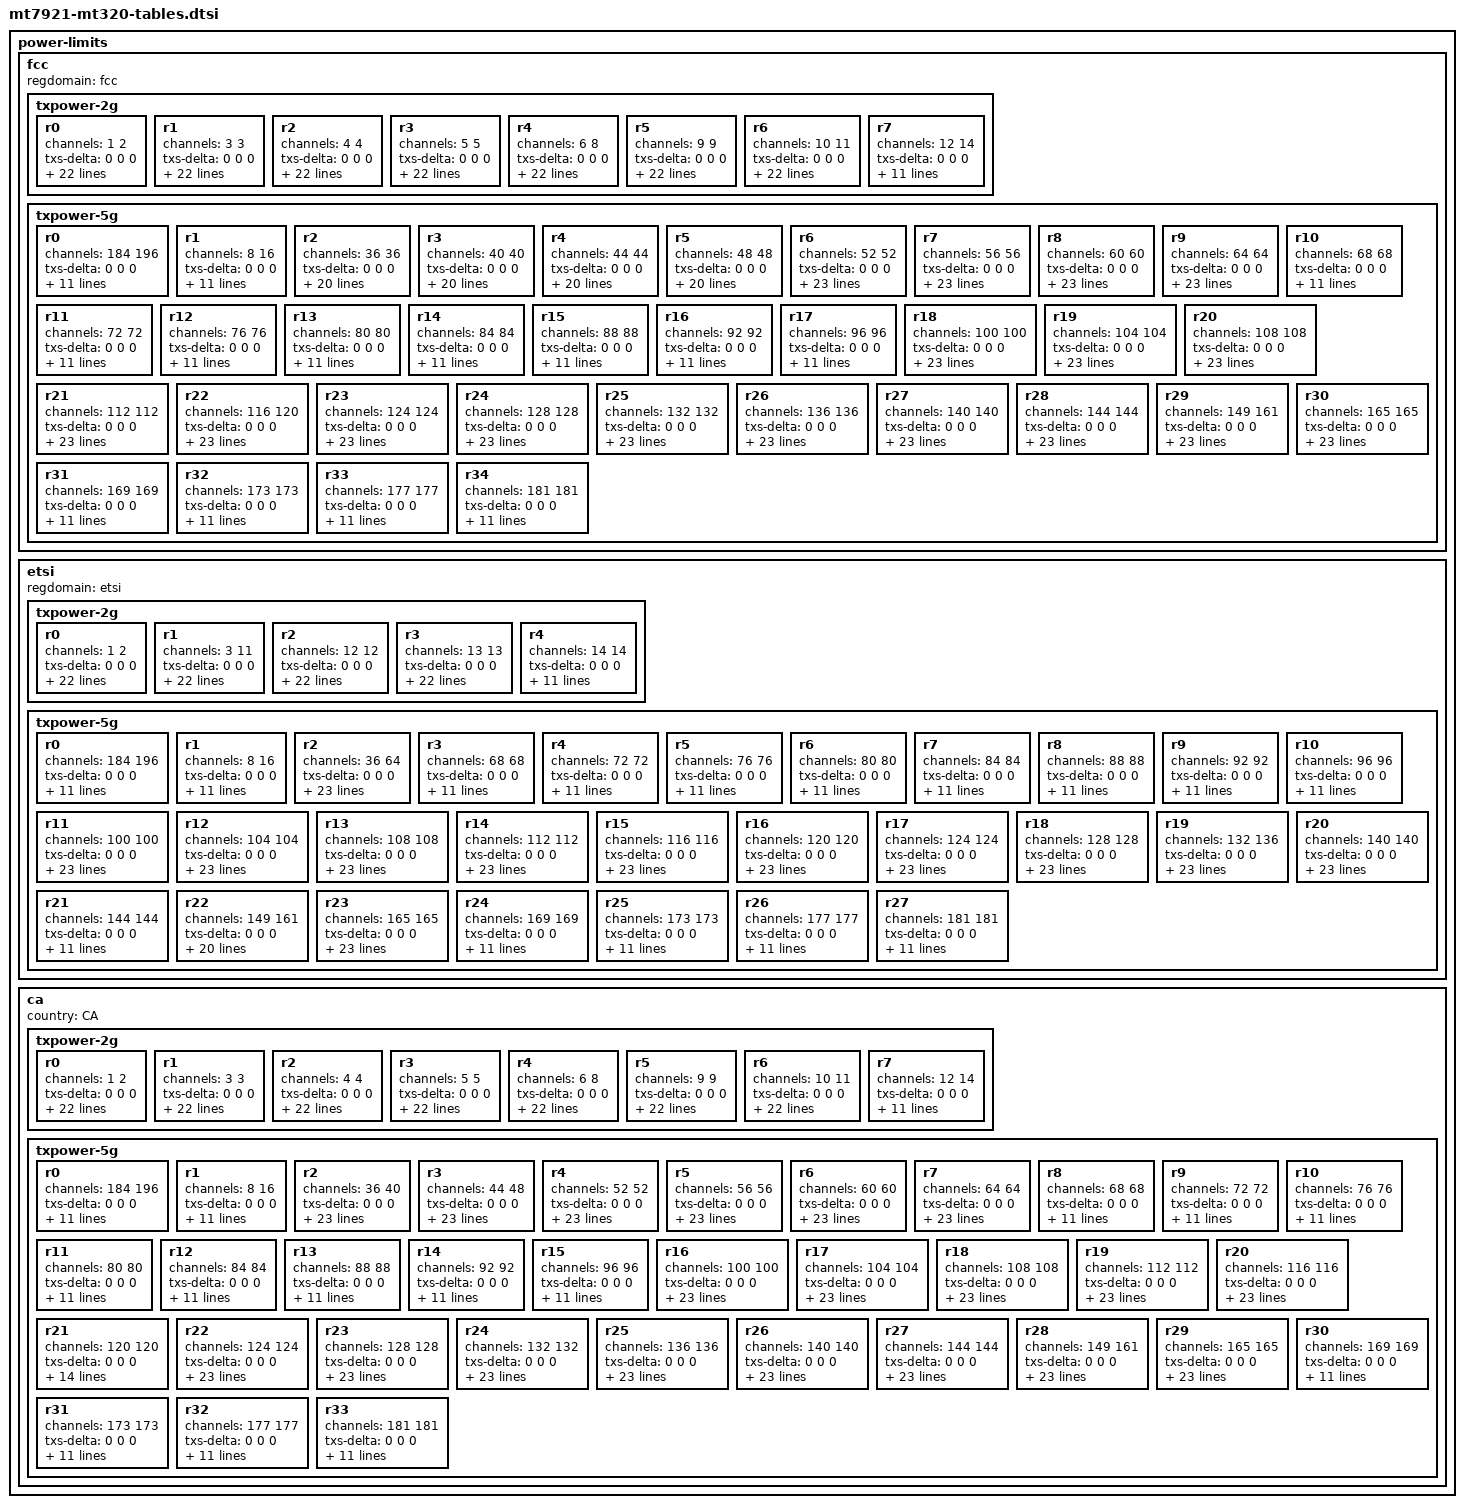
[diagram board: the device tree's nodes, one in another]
power-limits {
	fcc {
		regdomain = "fcc";
		txpower-2g {
			r0 {
				channels = <1 2>;
				txs-delta = <0 0 0>;
				rates-cck = <31 31 31 31>;
				rates-ofdm = <27 27 27 27 27 27 27 27>;
				rates-mcs =
				<1 20 20 20 20 20 20 20 20 20 20>,
				<1 20 0 0 0 0 0 0 0 0 0>,
				<2 126 126 126 126 126 126 126 126 126 126>;
				rates-ru =
				<1 26 26 26 26 26 26 26 26 26 0 0 0>,
				<1 0 0 0 0 0 0 0 0 0 0 0 0>,
				<1 0 18 18 18 18 18 18 18 18 18 18 18>,
				<1 20 20 20 20 20 20 20 20 20 20 20 20>,
				<1 20 0 0 0 0 0 0 0 0 0 0 0>,
				<2 126 126 126 126 126 126 126 126 126 126 126 126>;
				rates-eht-ru =
				<1 26 26 26 26 26 26 26 26 26 0 0 0 0 0 0 0>,
				<1 0 0 0 0 0 0 0 0 0 0 0 0 0 0 0 0>,
				<1 0 18 18 18 18 18 18 18 18 18 18 18 18 20 20 20>,
				<1 20 20 20 20 20 20 20 20 20 20 20 20 20 20 20 20>,
				<1 20 0 0 0 0 0 0 0 0 0 0 0 0 0 0 0>,
				<3 126 126 126 126 126 126 126 126 126 126 126 126 126 126 126 126>,
				<1 0 0 0 0 0 0 0 0 0 0 0 0 0 0 0 0>,
				<1 20 20 20 20 20 20 20 20 20 20 20 20 20 20 20 20>,
				<1 0 0 0 0 0 0 0 0 0 0 0 0 0 0 0 0>,
				<5 126 126 126 126 126 126 126 126 126 126 126 126 126 126 126 126>;
			};
			r1 {
				channels = <3 3>;
				txs-delta = <0 0 0>;
				rates-cck = <32 32 32 32>;
				rates-ofdm = <28 28 28 28 28 28 28 28>;
				rates-mcs =
				<1 20 20 20 20 20 20 20 20 20 20>,
				<1 20 21 21 21 21 21 21 21 21 21>,
				<2 126 126 126 126 126 126 126 126 126 126>;
				rates-ru =
				<1 28 28 28 28 28 28 28 28 28 0 0 0>,
				<1 21 21 21 21 21 21 0 0 0 0 0 0>,
				<1 0 20 20 20 20 20 20 20 20 20 20 20>,
				<1 20 20 20 20 20 20 20 20 20 20 20 20>,
				<1 20 21 21 21 21 21 21 21 21 21 21 21>,
				<2 126 126 126 126 126 126 126 126 126 126 126 126>;
				rates-eht-ru =
				<1 28 28 28 28 28 28 28 28 28 0 0 0 21 21 21 21>,
				<1 21 21 21 21 21 21 0 0 0 0 0 0 0 0 0 0>,
				<1 0 20 20 20 20 20 20 20 20 20 20 20 20 20 20 20>,
				<1 20 20 20 20 20 20 20 20 20 20 20 20 20 20 20 20>,
				<1 20 21 21 21 21 21 21 21 21 21 21 21 21 0 0 0>,
				<3 126 126 126 126 126 126 126 126 126 126 126 126 126 126 126 126>,
				<1 0 0 0 0 0 0 0 0 0 0 0 0 0 0 0 0>,
				<1 20 20 20 20 20 20 20 20 20 20 20 20 20 20 20 20>,
				<1 0 0 0 0 0 0 0 0 0 0 0 0 0 0 0 0>,
				<5 126 126 126 126 126 126 126 126 126 126 126 126 126 126 126 126>;
			};
			r2 {
				channels = <4 4>;
				txs-delta = <0 0 0>;
				rates-cck = <34 34 34 34>;
				rates-ofdm = <30 30 30 30 30 30 30 30>;
				rates-mcs =
				<1 22 22 22 22 22 22 22 22 22 22>,
				<1 22 21 21 21 21 21 21 21 21 21>,
				<2 126 126 126 126 126 126 126 126 126 126>;
				rates-ru =
				<1 30 30 30 30 30 30 30 30 30 0 0 0>,
				<1 21 21 21 21 21 21 0 0 0 0 0 0>,
				<1 0 22 22 22 22 22 22 22 22 22 22 22>,
				<1 22 22 22 22 22 22 22 22 22 22 22 22>,
				<1 22 21 21 21 21 21 21 21 21 21 21 21>,
				<2 126 126 126 126 126 126 126 126 126 126 126 126>;
				rates-eht-ru =
				<1 30 30 30 30 30 30 30 30 30 0 0 0 21 21 21 21>,
				<1 21 21 21 21 21 21 0 0 0 0 0 0 0 0 0 0>,
				<1 0 22 22 22 22 22 22 22 22 22 22 22 22 22 22 22>,
				<1 22 22 22 22 22 22 22 22 22 22 22 22 22 22 22 22>,
				<1 22 21 21 21 21 21 21 21 21 21 21 21 21 0 0 0>,
				<3 126 126 126 126 126 126 126 126 126 126 126 126 126 126 126 126>,
				<1 0 0 0 0 0 0 0 0 0 0 0 0 0 0 0 0>,
				<1 22 22 22 22 22 22 22 22 22 22 22 22 22 22 22 22>,
				<1 0 0 0 0 0 0 0 0 0 0 0 0 0 0 0 0>,
				<5 126 126 126 126 126 126 126 126 126 126 126 126 126 126 126 126>;
			};
			r3 {
				channels = <5 5>;
				txs-delta = <0 0 0>;
				rates-cck = <34 34 34 34>;
				rates-ofdm = <30 30 30 30 30 30 30 30>;
				rates-mcs =
				<1 26 26 26 26 26 24 24 24 24 24>,
				<1 24 21 21 21 21 21 21 21 21 21>,
				<2 126 126 126 126 126 126 126 126 126 126>;
				rates-ru =
				<1 30 30 30 30 30 30 30 30 30 0 0 0>,
				<1 21 21 21 21 21 21 0 0 0 0 0 0>,
				<1 0 26 26 26 26 26 26 26 26 26 26 26>,
				<1 26 26 26 26 26 24 24 24 24 24 24 24>,
				<1 24 21 21 21 21 21 21 21 21 21 21 21>,
				<2 126 126 126 126 126 126 126 126 126 126 126 126>;
				rates-eht-ru =
				<1 30 30 30 30 30 30 30 30 30 0 0 0 21 21 21 21>,
				<1 21 21 21 21 21 21 0 0 0 0 0 0 0 0 0 0>,
				<1 0 26 26 26 26 26 26 26 26 26 26 26 26 26 26 26>,
				<1 26 26 26 26 26 24 24 24 24 24 24 24 24 24 24 24>,
				<1 24 21 21 21 21 21 21 21 21 21 21 21 21 0 0 0>,
				<3 126 126 126 126 126 126 126 126 126 126 126 126 126 126 126 126>,
				<1 0 0 0 0 0 0 0 0 0 0 0 0 0 0 0 0>,
				<1 26 26 26 26 26 26 26 26 26 26 26 26 26 26 26 26>,
				<1 0 0 0 0 0 0 0 0 0 0 0 0 0 0 0 0>,
				<5 126 126 126 126 126 126 126 126 126 126 126 126 126 126 126 126>;
			};
			r4 {
				channels = <6 8>;
				txs-delta = <0 0 0>;
				rates-cck = <34 34 34 34>;
				rates-ofdm = <30 30 30 30 30 30 30 30>;
				rates-mcs =
				<1 26 26 26 26 26 26 26 26 26 26>,
				<1 26 21 21 21 21 21 21 21 21 21>,
				<2 126 126 126 126 126 126 126 126 126 126>;
				rates-ru =
				<1 30 30 30 30 30 30 30 30 30 0 0 0>,
				<1 21 21 21 21 21 21 0 0 0 0 0 0>,
				<1 0 28 28 28 28 28 28 28 28 28 28 28>,
				<1 26 26 26 26 26 26 26 26 26 26 26 26>,
				<1 26 21 21 21 21 21 21 21 21 21 21 21>,
				<2 126 126 126 126 126 126 126 126 126 126 126 126>;
				rates-eht-ru =
				<1 30 30 30 30 30 30 30 30 30 0 0 0 21 21 21 21>,
				<1 21 21 21 21 21 21 0 0 0 0 0 0 0 0 0 0>,
				<1 0 28 28 28 28 28 28 28 28 28 28 28 28 26 26 26>,
				<1 26 26 26 26 26 26 26 26 26 26 26 26 26 26 26 26>,
				<1 26 21 21 21 21 21 21 21 21 21 21 21 21 0 0 0>,
				<3 126 126 126 126 126 126 126 126 126 126 126 126 126 126 126 126>,
				<1 0 0 0 0 0 0 0 0 0 0 0 0 0 0 0 0>,
				<1 26 26 26 26 26 26 26 26 26 26 26 26 26 26 26 26>,
				<1 0 0 0 0 0 0 0 0 0 0 0 0 0 0 0 0>,
				<5 126 126 126 126 126 126 126 126 126 126 126 126 126 126 126 126>;
			};
			r5 {
				channels = <9 9>;
				txs-delta = <0 0 0>;
				rates-cck = <34 34 34 34>;
				rates-ofdm = <28 28 28 28 28 28 28 28>;
				rates-mcs =
				<1 23 23 23 23 23 24 24 24 24 24>,
				<1 24 21 21 21 21 21 21 21 21 21>,
				<2 126 126 126 126 126 126 126 126 126 126>;
				rates-ru =
				<1 27 27 27 27 27 27 27 27 27 0 0 0>,
				<1 21 21 21 21 21 21 0 0 0 0 0 0>,
				<1 0 26 26 26 26 26 26 26 26 26 26 26>,
				<1 23 23 23 23 23 24 24 24 24 24 24 24>,
				<1 24 21 21 21 21 21 21 21 21 21 21 21>,
				<2 126 126 126 126 126 126 126 126 126 126 126 126>;
				rates-eht-ru =
				<1 27 27 27 27 27 27 27 27 27 0 0 0 21 21 21 21>,
				<1 21 21 21 21 21 21 0 0 0 0 0 0 0 0 0 0>,
				<1 0 26 26 26 26 26 26 26 26 26 26 26 26 26 26 26>,
				<1 23 23 23 23 23 24 24 24 24 24 24 24 24 24 24 24>,
				<1 24 21 21 21 21 21 21 21 21 21 21 21 21 0 0 0>,
				<3 126 126 126 126 126 126 126 126 126 126 126 126 126 126 126 126>,
				<1 0 0 0 0 0 0 0 0 0 0 0 0 0 0 0 0>,
				<1 26 26 26 26 26 26 26 26 26 23 23 23 23 23 23 23>,
				<1 0 0 0 0 0 0 0 0 0 0 0 0 0 0 0 0>,
				<5 126 126 126 126 126 126 126 126 126 126 126 126 126 126 126 126>;
			};
			r6 {
				channels = <10 11>;
				txs-delta = <0 0 0>;
				rates-cck = <34 34 34 34>;
				rates-ofdm = <27 27 27 27 27 27 27 27>;
				rates-mcs =
				<1 21 21 21 21 21 24 24 24 24 24>,
				<1 24 0 0 0 0 0 0 0 0 0>,
				<2 126 126 126 126 126 126 126 126 126 126>;
				rates-ru =
				<1 25 25 25 25 25 25 25 25 25 0 0 0>,
				<1 0 0 0 0 0 0 0 0 0 0 0 0>,
				<1 0 22 22 22 22 22 22 22 22 22 22 22>,
				<1 21 21 21 21 21 24 24 24 24 24 24 24>,
				<1 24 0 0 0 0 0 0 0 0 0 0 0>,
				<2 126 126 126 126 126 126 126 126 126 126 126 126>;
				rates-eht-ru =
				<1 25 25 25 25 25 25 25 25 25 0 0 0 0 0 0 0>,
				<1 0 0 0 0 0 0 0 0 0 0 0 0 0 0 0 0>,
				<1 0 22 22 22 22 22 22 22 22 22 22 22 22 25 25 25>,
				<1 21 21 21 21 21 24 24 24 24 24 24 24 24 24 24 24>,
				<1 24 0 0 0 0 0 0 0 0 0 0 0 0 0 0 0>,
				<3 126 126 126 126 126 126 126 126 126 126 126 126 126 126 126 126>,
				<1 0 0 0 0 0 0 0 0 0 0 0 0 0 0 0 0>,
				<1 25 25 25 25 25 25 25 25 25 21 21 21 21 21 21 21>,
				<1 0 0 0 0 0 0 0 0 0 0 0 0 0 0 0 0>,
				<5 126 126 126 126 126 126 126 126 126 126 126 126 126 126 126 126>;
			};
			r7 {
				channels = <12 14>;
				txs-delta = <0 0 0>;
				rates-cck = <0 0 0 0>;
				rates-ofdm = <0 0 0 0 0 0 0 0>;
				rates-mcs =
				<2 0 0 0 0 0 0 0 0 0 0>,
				<2 126 126 126 126 126 126 126 126 126 126>;
				rates-ru =
				<5 0 0 0 0 0 0 0 0 0 0 0 0>,
				<2 126 126 126 126 126 126 126 126 126 126 126 126>;
				rates-eht-ru =
				<5 0 0 0 0 0 0 0 0 0 0 0 0 0 0 0 0>,
				<3 126 126 126 126 126 126 126 126 126 126 126 126 126 126 126 126>,
				<3 0 0 0 0 0 0 0 0 0 0 0 0 0 0 0 0>,
				<5 126 126 126 126 126 126 126 126 126 126 126 126 126 126 126 126>;
			};
		};
		txpower-5g {
			r0 {
				channels = <184 196>;
				txs-delta = <0 0 0>;
				rates-cck = <126 126 126 126>;
				rates-ofdm = <0 0 0 0 0 0 0 0>;
				rates-mcs =
				<2 0 0 0 0 0 0 0 0 0 0>,
				<2 126 126 126 126 126 126 126 126 126 126>;
				rates-ru =
				<5 0 0 0 0 0 0 0 0 0 0 0 0>,
				<2 126 126 126 126 126 126 126 126 126 126 126 126>;
				rates-eht-ru =
				<5 0 0 0 0 0 0 0 0 0 0 0 0 0 0 0 0>,
				<3 126 126 126 126 126 126 126 126 126 126 126 126 126 126 126 126>,
				<3 0 0 0 0 0 0 0 0 0 0 0 0 0 0 0 0>,
				<5 126 126 126 126 126 126 126 126 126 126 126 126 126 126 126 126>;
			};
			r1 {
				channels = <8 16>;
				txs-delta = <0 0 0>;
				rates-cck = <126 126 126 126>;
				rates-ofdm = <0 0 0 0 0 0 0 0>;
				rates-mcs =
				<2 0 0 0 0 0 0 0 0 0 0>,
				<2 126 126 126 126 126 126 126 126 126 126>;
				rates-ru =
				<5 0 0 0 0 0 0 0 0 0 0 0 0>,
				<2 126 126 126 126 126 126 126 126 126 126 126 126>;
				rates-eht-ru =
				<5 0 0 0 0 0 0 0 0 0 0 0 0 0 0 0 0>,
				<3 126 126 126 126 126 126 126 126 126 126 126 126 126 126 126 126>,
				<3 0 0 0 0 0 0 0 0 0 0 0 0 0 0 0 0>,
				<5 126 126 126 126 126 126 126 126 126 126 126 126 126 126 126 126>;
			};
			r2 {
				channels = <36 36>;
				txs-delta = <0 0 0>;
				rates-cck = <126 126 126 126>;
				rates-ofdm = <0 0 0 0 23 23 23 23>;
				rates-mcs =
				<2 22 22 22 22 22 22 22 22 22 22>,
				<2 126 126 126 126 126 126 126 126 126 126>;
				rates-ru =
				<1 23 23 23 23 23 23 23 23 23 23 23 23>,
				<1 22 22 22 22 22 22 22 22 22 22 0 0>,
				<1 0 0 0 0 0 18 18 18 18 18 18 18>,
				<2 22 22 22 22 22 22 22 22 22 22 22 22>,
				<2 126 126 126 126 126 126 126 126 126 126 126 126>;
				rates-eht-ru =
				<1 23 23 23 23 23 23 23 23 23 23 23 23 23 0 0 0>,
				<1 22 22 22 22 22 22 22 22 22 22 0 0 0 16 16 16>,
				<1 0 0 0 0 0 18 18 18 18 18 18 18 18 18 18 18>,
				<2 22 22 22 22 22 22 22 22 22 22 22 22 22 22 22 22>,
				<3 126 126 126 126 126 126 126 126 126 126 126 126 126 126 126 126>,
				<1 16 16 16 16 16 16 16 0 0 0 0 0 0 0 0 0>,
				<1 18 18 18 18 18 18 18 18 18 18 18 18 18 22 22 22>,
				<1 16 16 16 16 16 16 16 16 16 16 16 16 0 0 0 0>,
				<5 126 126 126 126 126 126 126 126 126 126 126 126 126 126 126 126>;
			};
			r3 {
				channels = <40 40>;
				txs-delta = <0 0 0>;
				rates-cck = <126 126 126 126>;
				rates-ofdm = <0 0 0 0 26 26 26 26>;
				rates-mcs =
				<2 22 22 22 22 22 22 22 22 22 22>,
				<2 126 126 126 126 126 126 126 126 126 126>;
				rates-ru =
				<1 26 26 26 26 27 27 27 27 27 27 27 27>,
				<1 22 22 22 22 22 22 22 22 22 22 0 0>,
				<1 0 0 0 0 0 18 18 18 18 18 18 18>,
				<2 22 22 22 22 22 22 22 22 22 22 22 22>,
				<2 126 126 126 126 126 126 126 126 126 126 126 126>;
				rates-eht-ru =
				<1 26 26 26 26 27 27 27 27 27 27 27 27 27 0 0 0>,
				<1 22 22 22 22 22 22 22 22 22 22 0 0 0 16 16 16>,
				<1 0 0 0 0 0 18 18 18 18 18 18 18 18 18 18 18>,
				<2 22 22 22 22 22 22 22 22 22 22 22 22 22 22 22 22>,
				<3 126 126 126 126 126 126 126 126 126 126 126 126 126 126 126 126>,
				<1 16 16 16 16 16 16 16 0 0 0 0 0 0 0 0 0>,
				<1 18 18 18 18 18 18 18 18 18 18 18 18 18 22 22 22>,
				<1 16 16 16 16 16 16 16 16 16 16 16 16 0 0 0 0>,
				<5 126 126 126 126 126 126 126 126 126 126 126 126 126 126 126 126>;
			};
			r4 {
				channels = <44 44>;
				txs-delta = <0 0 0>;
				rates-cck = <126 126 126 126>;
				rates-ofdm = <0 0 0 0 30 30 30 30>;
				rates-mcs =
				<2 22 22 22 22 22 22 22 22 22 22>,
				<2 126 126 126 126 126 126 126 126 126 126>;
				rates-ru =
				<1 30 30 30 30 31 31 31 31 31 31 31 31>,
				<1 27 27 27 27 27 27 27 27 27 27 0 0>,
				<1 0 0 0 0 0 18 18 18 18 18 18 18>,
				<2 22 22 22 22 22 22 22 22 22 22 22 22>,
				<2 126 126 126 126 126 126 126 126 126 126 126 126>;
				rates-eht-ru =
				<1 30 30 30 30 31 31 31 31 31 31 31 31 31 0 0 0>,
				<1 27 27 27 27 27 27 27 27 27 27 0 0 0 16 16 16>,
				<1 0 0 0 0 0 18 18 18 18 18 18 18 18 18 18 18>,
				<2 22 22 22 22 22 22 22 22 22 22 22 22 22 22 22 22>,
				<3 126 126 126 126 126 126 126 126 126 126 126 126 126 126 126 126>,
				<1 16 16 16 16 16 16 16 0 0 0 0 0 0 0 0 0>,
				<1 18 20 20 20 20 20 20 20 20 20 20 20 20 22 22 22>,
				<1 16 16 16 16 16 16 16 16 16 16 16 16 0 0 0 0>,
				<5 126 126 126 126 126 126 126 126 126 126 126 126 126 126 126 126>;
			};
			r5 {
				channels = <48 48>;
				txs-delta = <0 0 0>;
				rates-cck = <126 126 126 126>;
				rates-ofdm = <0 0 0 0 33 33 33 33>;
				rates-mcs =
				<2 22 22 22 22 22 22 22 22 22 22>,
				<2 126 126 126 126 126 126 126 126 126 126>;
				rates-ru =
				<1 33 33 32 32 32 32 32 32 32 32 32 32>,
				<1 27 27 27 27 27 27 27 27 27 27 0 0>,
				<1 0 0 0 0 0 18 18 18 18 18 18 18>,
				<2 22 22 22 22 22 22 22 22 22 22 22 22>,
				<2 126 126 126 126 126 126 126 126 126 126 126 126>;
				rates-eht-ru =
				<1 33 33 32 32 32 32 32 32 32 32 32 32 32 0 0 0>,
				<1 27 27 27 27 27 27 27 27 27 27 0 0 0 16 16 16>,
				<1 0 0 0 0 0 18 18 18 18 18 18 18 18 18 18 18>,
				<2 22 22 22 22 22 22 22 22 22 22 22 22 22 22 22 22>,
				<3 126 126 126 126 126 126 126 126 126 126 126 126 126 126 126 126>,
				<1 16 16 16 16 16 16 16 0 0 0 0 0 0 0 0 0>,
				<1 18 20 20 20 20 20 20 20 20 20 20 20 20 22 22 22>,
				<1 16 16 16 16 16 16 16 16 16 16 16 16 0 0 0 0>,
				<5 126 126 126 126 126 126 126 126 126 126 126 126 126 126 126 126>;
			};
			r6 {
				channels = <52 52>;
				txs-delta = <0 0 0>;
				rates-cck = <126 126 126 126>;
				rates-ofdm = <0 0 0 0 31 31 31 31>;
				rates-mcs =
				<1 22 22 22 22 22 22 22 22 22 24>,
				<1 24 24 24 24 24 22 22 22 22 22>,
				<2 126 126 126 126 126 126 126 126 126 126>;
				rates-ru =
				<1 31 31 31 31 32 32 32 32 32 32 32 32>,
				<1 27 27 27 27 27 27 27 27 27 27 0 0>,
				<1 0 0 0 0 0 18 18 18 18 18 18 18>,
				<1 22 22 22 22 22 22 22 22 22 24 24 24>,
				<1 24 24 24 24 24 22 22 22 22 22 22 22>,
				<2 126 126 126 126 126 126 126 126 126 126 126 126>;
				rates-eht-ru =
				<1 31 31 31 31 32 32 32 32 32 32 32 32 32 0 0 0>,
				<1 27 27 27 27 27 27 27 27 27 27 0 0 0 18 18 18>,
				<1 0 0 0 0 0 18 18 18 18 18 18 18 18 18 18 18>,
				<1 22 22 22 22 22 22 22 22 22 24 24 24 24 24 24 24>,
				<1 24 24 24 24 24 22 22 22 22 22 22 22 22 22 22 22>,
				<3 126 126 126 126 126 126 126 126 126 126 126 126 126 126 126 126>,
				<1 18 18 18 18 18 18 18 0 0 0 0 0 0 0 0 0>,
				<1 18 20 20 20 20 20 20 20 20 20 20 20 20 22 22 22>,
				<1 18 18 18 18 18 18 18 18 18 18 18 18 0 0 0 0>,
				<5 126 126 126 126 126 126 126 126 126 126 126 126 126 126 126 126>;
			};
			r7 {
				channels = <56 56>;
				txs-delta = <0 0 0>;
				rates-cck = <126 126 126 126>;
				rates-ofdm = <0 0 0 0 30 30 30 30>;
				rates-mcs =
				<1 22 22 22 22 22 22 22 22 22 24>,
				<1 24 24 24 24 24 22 22 22 22 22>,
				<2 126 126 126 126 126 126 126 126 126 126>;
				rates-ru =
				<1 30 30 30 30 31 31 31 31 31 31 31 31>,
				<1 27 27 27 27 27 27 27 27 27 27 0 0>,
				<1 0 0 0 0 0 18 18 18 18 18 18 18>,
				<1 22 22 22 22 22 22 22 22 22 24 24 24>,
				<1 24 24 24 24 24 22 22 22 22 22 22 22>,
				<2 126 126 126 126 126 126 126 126 126 126 126 126>;
				rates-eht-ru =
				<1 30 30 30 30 31 31 31 31 31 31 31 31 31 0 0 0>,
				<1 27 27 27 27 27 27 27 27 27 27 0 0 0 18 18 18>,
				<1 0 0 0 0 0 18 18 18 18 18 18 18 18 18 18 18>,
				<1 22 22 22 22 22 22 22 22 22 24 24 24 24 24 24 24>,
				<1 24 24 24 24 24 22 22 22 22 22 22 22 22 22 22 22>,
				<3 126 126 126 126 126 126 126 126 126 126 126 126 126 126 126 126>,
				<1 18 18 18 18 18 18 18 0 0 0 0 0 0 0 0 0>,
				<1 18 20 20 20 20 20 20 20 20 20 20 20 20 22 22 22>,
				<1 18 18 18 18 18 18 18 18 18 18 18 18 0 0 0 0>,
				<5 126 126 126 126 126 126 126 126 126 126 126 126 126 126 126 126>;
			};
			r8 {
				channels = <60 60>;
				txs-delta = <0 0 0>;
				rates-cck = <126 126 126 126>;
				rates-ofdm = <0 0 0 0 28 28 28 28>;
				rates-mcs =
				<1 22 22 22 22 22 22 22 22 22 23>,
				<1 23 23 23 23 23 22 22 22 22 22>,
				<2 126 126 126 126 126 126 126 126 126 126>;
				rates-ru =
				<1 28 28 28 28 27 27 27 27 27 27 27 27>,
				<1 22 22 22 22 22 22 22 22 22 22 0 0>,
				<1 0 0 0 0 0 18 18 18 18 18 18 18>,
				<1 22 22 22 22 22 22 22 22 22 23 23 23>,
				<1 23 23 23 23 23 22 22 22 22 22 22 22>,
				<2 126 126 126 126 126 126 126 126 126 126 126 126>;
				rates-eht-ru =
				<1 28 28 28 28 27 27 27 27 27 27 27 27 27 0 0 0>,
				<1 22 22 22 22 22 22 22 22 22 22 0 0 0 18 18 18>,
				<1 0 0 0 0 0 18 18 18 18 18 18 18 18 18 18 18>,
				<1 22 22 22 22 22 22 22 22 22 23 23 23 23 23 23 23>,
				<1 23 23 23 23 23 22 22 22 22 22 22 22 22 22 22 22>,
				<3 126 126 126 126 126 126 126 126 126 126 126 126 126 126 126 126>,
				<1 18 18 18 18 18 18 18 0 0 0 0 0 0 0 0 0>,
				<1 18 20 20 20 20 20 20 20 20 20 20 20 20 22 22 22>,
				<1 18 18 18 18 18 18 18 18 18 18 18 18 0 0 0 0>,
				<5 126 126 126 126 126 126 126 126 126 126 126 126 126 126 126 126>;
			};
			r9 {
				channels = <64 64>;
				txs-delta = <0 0 0>;
				rates-cck = <126 126 126 126>;
				rates-ofdm = <0 0 0 0 24 24 24 24>;
				rates-mcs =
				<1 20 20 20 20 20 20 20 20 20 23>,
				<1 23 23 23 23 23 22 22 22 22 22>,
				<2 126 126 126 126 126 126 126 126 126 126>;
				rates-ru =
				<1 24 24 24 24 24 24 24 24 24 24 24 24>,
				<1 22 22 22 22 22 22 22 22 22 22 0 0>,
				<1 0 0 0 0 0 18 18 18 18 18 18 18>,
				<1 20 20 20 20 20 20 20 20 20 23 23 23>,
				<1 23 23 23 23 23 22 22 22 22 22 22 22>,
				<2 126 126 126 126 126 126 126 126 126 126 126 126>;
				rates-eht-ru =
				<1 24 24 24 24 24 24 24 24 24 24 24 24 24 0 0 0>,
				<1 22 22 22 22 22 22 22 22 22 22 0 0 0 18 18 18>,
				<1 0 0 0 0 0 18 18 18 18 18 18 18 18 18 18 18>,
				<1 20 20 20 20 20 20 20 20 20 23 23 23 23 23 23 23>,
				<1 23 23 23 23 23 22 22 22 22 22 22 22 22 22 22 22>,
				<3 126 126 126 126 126 126 126 126 126 126 126 126 126 126 126 126>,
				<1 18 18 18 18 18 18 18 0 0 0 0 0 0 0 0 0>,
				<1 18 20 20 20 20 20 20 20 20 20 20 20 20 20 20 20>,
				<1 18 18 18 18 18 18 18 18 18 18 18 18 0 0 0 0>,
				<5 126 126 126 126 126 126 126 126 126 126 126 126 126 126 126 126>;
			};
			r10 {
				channels = <68 68>;
				txs-delta = <0 0 0>;
				rates-cck = <126 126 126 126>;
				rates-ofdm = <0 0 0 0 0 0 0 0>;
				rates-mcs =
				<2 0 0 0 0 0 0 0 0 0 0>,
				<2 126 126 126 126 126 126 126 126 126 126>;
				rates-ru =
				<5 0 0 0 0 0 0 0 0 0 0 0 0>,
				<2 126 126 126 126 126 126 126 126 126 126 126 126>;
				rates-eht-ru =
				<5 0 0 0 0 0 0 0 0 0 0 0 0 0 0 0 0>,
				<3 126 126 126 126 126 126 126 126 126 126 126 126 126 126 126 126>,
				<3 0 0 0 0 0 0 0 0 0 0 0 0 0 0 0 0>,
				<5 126 126 126 126 126 126 126 126 126 126 126 126 126 126 126 126>;
			};
			r11 {
				channels = <72 72>;
				txs-delta = <0 0 0>;
				rates-cck = <126 126 126 126>;
				rates-ofdm = <0 0 0 0 0 0 0 0>;
				rates-mcs =
				<2 0 0 0 0 0 0 0 0 0 0>,
				<2 126 126 126 126 126 126 126 126 126 126>;
				rates-ru =
				<5 0 0 0 0 0 0 0 0 0 0 0 0>,
				<2 126 126 126 126 126 126 126 126 126 126 126 126>;
				rates-eht-ru =
				<5 0 0 0 0 0 0 0 0 0 0 0 0 0 0 0 0>,
				<3 126 126 126 126 126 126 126 126 126 126 126 126 126 126 126 126>,
				<3 0 0 0 0 0 0 0 0 0 0 0 0 0 0 0 0>,
				<5 126 126 126 126 126 126 126 126 126 126 126 126 126 126 126 126>;
			};
			r12 {
				channels = <76 76>;
				txs-delta = <0 0 0>;
				rates-cck = <126 126 126 126>;
				rates-ofdm = <0 0 0 0 0 0 0 0>;
				rates-mcs =
				<2 0 0 0 0 0 0 0 0 0 0>,
				<2 126 126 126 126 126 126 126 126 126 126>;
				rates-ru =
				<5 0 0 0 0 0 0 0 0 0 0 0 0>,
				<2 126 126 126 126 126 126 126 126 126 126 126 126>;
				rates-eht-ru =
				<5 0 0 0 0 0 0 0 0 0 0 0 0 0 0 0 0>,
				<3 126 126 126 126 126 126 126 126 126 126 126 126 126 126 126 126>,
				<3 0 0 0 0 0 0 0 0 0 0 0 0 0 0 0 0>,
				<5 126 126 126 126 126 126 126 126 126 126 126 126 126 126 126 126>;
			};
			r13 {
				channels = <80 80>;
				txs-delta = <0 0 0>;
				rates-cck = <126 126 126 126>;
				rates-ofdm = <0 0 0 0 0 0 0 0>;
				rates-mcs =
				<2 0 0 0 0 0 0 0 0 0 0>,
				<2 126 126 126 126 126 126 126 126 126 126>;
				rates-ru =
				<5 0 0 0 0 0 0 0 0 0 0 0 0>,
				<2 126 126 126 126 126 126 126 126 126 126 126 126>;
				rates-eht-ru =
				<5 0 0 0 0 0 0 0 0 0 0 0 0 0 0 0 0>,
				<3 126 126 126 126 126 126 126 126 126 126 126 126 126 126 126 126>,
				<3 0 0 0 0 0 0 0 0 0 0 0 0 0 0 0 0>,
				<5 126 126 126 126 126 126 126 126 126 126 126 126 126 126 126 126>;
			};
			r14 {
				channels = <84 84>;
				txs-delta = <0 0 0>;
				rates-cck = <126 126 126 126>;
				rates-ofdm = <0 0 0 0 0 0 0 0>;
				rates-mcs =
				<2 0 0 0 0 0 0 0 0 0 0>,
				<2 126 126 126 126 126 126 126 126 126 126>;
				rates-ru =
				<5 0 0 0 0 0 0 0 0 0 0 0 0>,
				<2 126 126 126 126 126 126 126 126 126 126 126 126>;
				rates-eht-ru =
				<5 0 0 0 0 0 0 0 0 0 0 0 0 0 0 0 0>,
				<3 126 126 126 126 126 126 126 126 126 126 126 126 126 126 126 126>,
				<3 0 0 0 0 0 0 0 0 0 0 0 0 0 0 0 0>,
				<5 126 126 126 126 126 126 126 126 126 126 126 126 126 126 126 126>;
			};
			r15 {
				channels = <88 88>;
				txs-delta = <0 0 0>;
				rates-cck = <126 126 126 126>;
				rates-ofdm = <0 0 0 0 0 0 0 0>;
				rates-mcs =
				<2 0 0 0 0 0 0 0 0 0 0>,
				<2 126 126 126 126 126 126 126 126 126 126>;
				rates-ru =
				<5 0 0 0 0 0 0 0 0 0 0 0 0>,
				<2 126 126 126 126 126 126 126 126 126 126 126 126>;
				rates-eht-ru =
				<5 0 0 0 0 0 0 0 0 0 0 0 0 0 0 0 0>,
				<3 126 126 126 126 126 126 126 126 126 126 126 126 126 126 126 126>,
				<3 0 0 0 0 0 0 0 0 0 0 0 0 0 0 0 0>,
				<5 126 126 126 126 126 126 126 126 126 126 126 126 126 126 126 126>;
			};
			r16 {
				channels = <92 92>;
				txs-delta = <0 0 0>;
				rates-cck = <126 126 126 126>;
				rates-ofdm = <0 0 0 0 0 0 0 0>;
				rates-mcs =
				<2 0 0 0 0 0 0 0 0 0 0>,
				<2 126 126 126 126 126 126 126 126 126 126>;
				rates-ru =
				<5 0 0 0 0 0 0 0 0 0 0 0 0>,
				<2 126 126 126 126 126 126 126 126 126 126 126 126>;
				rates-eht-ru =
				<5 0 0 0 0 0 0 0 0 0 0 0 0 0 0 0 0>,
				<3 126 126 126 126 126 126 126 126 126 126 126 126 126 126 126 126>,
				<3 0 0 0 0 0 0 0 0 0 0 0 0 0 0 0 0>,
				<5 126 126 126 126 126 126 126 126 126 126 126 126 126 126 126 126>;
			};
			r17 {
				channels = <96 96>;
				txs-delta = <0 0 0>;
				rates-cck = <126 126 126 126>;
				rates-ofdm = <0 0 0 0 0 0 0 0>;
				rates-mcs =
				<2 0 0 0 0 0 0 0 0 0 0>,
				<2 126 126 126 126 126 126 126 126 126 126>;
				rates-ru =
				<5 0 0 0 0 0 0 0 0 0 0 0 0>,
				<2 126 126 126 126 126 126 126 126 126 126 126 126>;
				rates-eht-ru =
				<5 0 0 0 0 0 0 0 0 0 0 0 0 0 0 0 0>,
				<3 126 126 126 126 126 126 126 126 126 126 126 126 126 126 126 126>,
				<3 0 0 0 0 0 0 0 0 0 0 0 0 0 0 0 0>,
				<5 126 126 126 126 126 126 126 126 126 126 126 126 126 126 126 126>;
			};
			r18 {
				channels = <100 100>;
				txs-delta = <0 0 0>;
				rates-cck = <126 126 126 126>;
				rates-ofdm = <0 0 0 0 24 24 24 24>;
				rates-mcs =
				<1 20 20 20 20 20 20 20 20 20 24>,
				<1 24 24 24 24 24 20 20 20 20 20>,
				<2 126 126 126 126 126 126 126 126 126 126>;
				rates-ru =
				<1 24 24 24 24 25 25 25 25 25 25 25 25>,
				<1 24 24 24 24 24 24 24 24 24 24 0 0>,
				<1 0 0 0 0 0 16 16 16 16 16 16 16>,
				<1 20 20 20 20 20 20 20 20 20 24 24 24>,
				<1 24 24 24 24 24 20 20 20 20 20 20 20>,
				<2 126 126 126 126 126 126 126 126 126 126 126 126>;
				rates-eht-ru =
				<1 24 24 24 24 25 25 25 25 25 25 25 25 25 0 0 0>,
				<1 24 24 24 24 24 24 24 24 24 24 0 0 0 22 22 22>,
				<1 0 0 0 0 0 16 16 16 16 16 16 16 16 16 16 16>,
				<1 20 20 20 20 20 20 20 20 20 24 24 24 24 24 24 24>,
				<1 24 24 24 24 24 20 20 20 20 20 20 20 20 20 20 20>,
				<3 126 126 126 126 126 126 126 126 126 126 126 126 126 126 126 126>,
				<1 22 22 22 22 22 22 22 0 0 0 0 0 0 0 0 0>,
				<1 16 18 18 18 18 18 18 18 18 18 18 18 18 20 20 20>,
				<1 22 22 22 22 22 22 22 22 22 22 22 22 0 0 0 0>,
				<5 126 126 126 126 126 126 126 126 126 126 126 126 126 126 126 126>;
			};
			r19 {
				channels = <104 104>;
				txs-delta = <0 0 0>;
				rates-cck = <126 126 126 126>;
				rates-ofdm = <0 0 0 0 28 28 28 28>;
				rates-mcs =
				<1 20 20 20 20 20 20 20 20 20 24>,
				<1 24 24 24 24 24 20 20 20 20 20>,
				<2 126 126 126 126 126 126 126 126 126 126>;
				rates-ru =
				<1 28 28 28 28 29 29 29 29 29 29 29 29>,
				<1 24 24 24 24 24 24 24 24 24 24 0 0>,
				<1 0 0 0 0 0 16 16 16 16 16 16 16>,
				<1 20 20 20 20 20 20 20 20 20 24 24 24>,
				<1 24 24 24 24 24 20 20 20 20 20 20 20>,
				<2 126 126 126 126 126 126 126 126 126 126 126 126>;
				rates-eht-ru =
				<1 28 28 28 28 29 29 29 29 29 29 29 29 29 0 0 0>,
				<1 24 24 24 24 24 24 24 24 24 24 0 0 0 22 22 22>,
				<1 0 0 0 0 0 16 16 16 16 16 16 16 16 16 16 16>,
				<1 20 20 20 20 20 20 20 20 20 24 24 24 24 24 24 24>,
				<1 24 24 24 24 24 20 20 20 20 20 20 20 20 20 20 20>,
				<3 126 126 126 126 126 126 126 126 126 126 126 126 126 126 126 126>,
				<1 22 22 22 22 22 22 22 0 0 0 0 0 0 0 0 0>,
				<1 16 18 18 18 18 18 18 18 18 18 18 18 18 20 20 20>,
				<1 22 22 22 22 22 22 22 22 22 22 22 22 0 0 0 0>,
				<5 126 126 126 126 126 126 126 126 126 126 126 126 126 126 126 126>;
			};
			r20 {
				channels = <108 108>;
				txs-delta = <0 0 0>;
				rates-cck = <126 126 126 126>;
				rates-ofdm = <0 0 0 0 32 32 32 32>;
				rates-mcs =
				<1 20 20 20 20 20 20 20 20 20 24>,
				<1 24 24 24 24 24 20 20 20 20 20>,
				<2 126 126 126 126 126 126 126 126 126 126>;
				rates-ru =
				<1 32 32 32 32 33 33 33 33 33 32 32 32>,
				<1 28 28 28 28 28 28 28 28 28 28 0 0>,
				<1 0 0 0 0 0 16 16 16 16 16 16 16>,
				<1 20 20 20 20 20 20 20 20 20 24 24 24>,
				<1 24 24 24 24 24 20 20 20 20 20 20 20>,
				<2 126 126 126 126 126 126 126 126 126 126 126 126>;
				rates-eht-ru =
				<1 32 32 32 32 33 33 33 33 33 32 32 32 32 0 0 0>,
				<1 28 28 28 28 28 28 28 28 28 28 0 0 0 22 22 22>,
				<1 0 0 0 0 0 16 16 16 16 16 16 16 16 16 16 16>,
				<1 20 20 20 20 20 20 20 20 20 24 24 24 24 24 24 24>,
				<1 24 24 24 24 24 20 20 20 20 20 20 20 20 20 20 20>,
				<3 126 126 126 126 126 126 126 126 126 126 126 126 126 126 126 126>,
				<1 22 22 22 22 22 22 22 0 0 0 0 0 0 0 0 0>,
				<1 16 20 20 20 20 20 20 20 20 20 20 20 20 20 20 20>,
				<1 22 22 22 22 22 22 22 22 22 22 22 22 0 0 0 0>,
				<5 126 126 126 126 126 126 126 126 126 126 126 126 126 126 126 126>;
			};
			r21 {
				channels = <112 112>;
				txs-delta = <0 0 0>;
				rates-cck = <126 126 126 126>;
				rates-ofdm = <0 0 0 0 33 33 33 33>;
				rates-mcs =
				<1 20 20 20 20 20 20 20 20 20 24>,
				<1 24 24 24 24 24 20 20 20 20 20>,
				<2 126 126 126 126 126 126 126 126 126 126>;
				rates-ru =
				<1 33 33 32 32 33 33 33 33 33 32 32 32>,
				<1 28 28 28 28 28 28 28 28 28 28 0 0>,
				<1 0 0 0 0 0 16 16 16 16 16 16 16>,
				<1 20 20 20 20 20 20 20 20 20 24 24 24>,
				<1 24 24 24 24 24 20 20 20 20 20 20 20>,
				<2 126 126 126 126 126 126 126 126 126 126 126 126>;
				rates-eht-ru =
				<1 33 33 32 32 33 33 33 33 33 32 32 32 32 0 0 0>,
				<1 28 28 28 28 28 28 28 28 28 28 0 0 0 22 22 22>,
				<1 0 0 0 0 0 16 16 16 16 16 16 16 16 16 16 16>,
				<1 20 20 20 20 20 20 20 20 20 24 24 24 24 24 24 24>,
				<1 24 24 24 24 24 20 20 20 20 20 20 20 20 20 20 20>,
				<3 126 126 126 126 126 126 126 126 126 126 126 126 126 126 126 126>,
				<1 22 22 22 22 22 22 22 0 0 0 0 0 0 0 0 0>,
				<1 16 20 20 20 20 20 20 20 20 20 20 20 20 20 20 20>,
				<1 22 22 22 22 22 22 22 22 22 22 22 22 0 0 0 0>,
				<5 126 126 126 126 126 126 126 126 126 126 126 126 126 126 126 126>;
			};
			r22 {
				channels = <116 120>;
				txs-delta = <0 0 0>;
				rates-cck = <126 126 126 126>;
				rates-ofdm = <0 0 0 0 33 33 33 33>;
				rates-mcs =
				<1 26 26 26 26 26 26 26 24 24 28>,
				<1 28 28 28 24 24 30 30 30 30 30>,
				<2 126 126 126 126 126 126 126 126 126 126>;
				rates-ru =
				<1 33 33 32 32 33 33 33 33 33 32 32 32>,
				<1 32 32 32 32 32 30 30 30 28 28 0 0>,
				<1 0 0 0 0 0 13 13 13 13 13 13 13>,
				<1 26 26 26 26 26 26 26 24 24 28 28 28>,
				<1 28 28 28 24 24 30 30 30 30 30 30 30>,
				<2 126 126 126 126 126 126 126 126 126 126 126 126>;
				rates-eht-ru =
				<1 33 33 32 32 33 33 33 33 33 32 32 32 32 0 0 0>,
				<1 32 32 32 32 32 30 30 30 28 28 0 0 0 30 30 30>,
				<1 0 0 0 0 0 13 13 13 13 13 13 13 13 13 13 13>,
				<1 26 26 26 26 26 26 26 24 24 28 28 28 28 28 28 28>,
				<1 28 28 28 24 24 30 30 30 30 30 30 30 30 28 28 24>,
				<3 126 126 126 126 126 126 126 126 126 126 126 126 126 126 126 126>,
				<1 30 30 30 30 30 28 28 0 0 0 0 0 0 0 0 0>,
				<1 13 20 20 20 20 20 20 20 20 20 20 20 20 26 26 26>,
				<1 30 30 30 30 30 30 30 30 28 28 24 24 0 0 0 0>,
				<5 126 126 126 126 126 126 126 126 126 126 126 126 126 126 126 126>;
			};
			r23 {
				channels = <124 124>;
				txs-delta = <0 0 0>;
				rates-cck = <126 126 126 126>;
				rates-ofdm = <0 0 0 0 33 33 33 33>;
				rates-mcs =
				<1 26 26 26 26 26 26 26 24 24 28>,
				<1 28 28 28 24 24 30 30 30 30 30>,
				<2 126 126 126 126 126 126 126 126 126 126>;
				rates-ru =
				<1 33 33 32 32 33 33 33 33 33 32 32 32>,
				<1 30 30 30 30 30 30 30 30 28 28 0 0>,
				<1 0 0 0 0 0 10 10 10 10 10 10 10>,
				<1 26 26 26 26 26 26 26 24 24 28 28 28>,
				<1 28 28 28 24 24 30 30 30 30 30 30 30>,
				<2 126 126 126 126 126 126 126 126 126 126 126 126>;
				rates-eht-ru =
				<1 33 33 32 32 33 33 33 33 33 32 32 32 32 0 0 0>,
				<1 30 30 30 30 30 30 30 30 28 28 0 0 0 30 30 30>,
				<1 0 0 0 0 0 10 10 10 10 10 10 10 10 10 10 10>,
				<1 26 26 26 26 26 26 26 24 24 28 28 28 28 28 28 28>,
				<1 28 28 28 24 24 30 30 30 30 30 30 30 30 28 28 24>,
				<3 126 126 126 126 126 126 126 126 126 126 126 126 126 126 126 126>,
				<1 30 30 30 30 30 28 28 0 0 0 0 0 0 0 0 0>,
				<1 10 20 20 20 20 20 20 20 20 20 20 20 20 26 26 26>,
				<1 30 30 30 30 30 30 30 30 28 28 24 24 0 0 0 0>,
				<5 126 126 126 126 126 126 126 126 126 126 126 126 126 126 126 126>;
			};
			r24 {
				channels = <128 128>;
				txs-delta = <0 0 0>;
				rates-cck = <126 126 126 126>;
				rates-ofdm = <0 0 0 0 33 33 33 33>;
				rates-mcs =
				<1 26 26 26 26 26 26 26 24 24 28>,
				<1 28 28 28 24 24 30 30 30 30 30>,
				<2 126 126 126 126 126 126 126 126 126 126>;
				rates-ru =
				<1 33 33 32 32 33 33 33 33 33 32 32 32>,
				<1 30 30 30 30 30 30 30 30 28 28 0 0>,
				<1 0 0 0 0 0 10 10 10 10 10 10 10>,
				<1 26 26 26 26 26 26 26 24 24 28 28 28>,
				<1 28 28 28 24 24 30 30 30 30 30 30 30>,
				<2 126 126 126 126 126 126 126 126 126 126 126 126>;
				rates-eht-ru =
				<1 33 33 32 32 33 33 33 33 33 32 32 32 32 0 0 0>,
				<1 30 30 30 30 30 30 30 30 28 28 0 0 0 30 30 30>,
				<1 0 0 0 0 0 10 10 10 10 10 10 10 10 10 10 10>,
				<1 26 26 26 26 26 26 26 24 24 28 28 28 28 28 28 28>,
				<1 28 28 28 24 24 30 30 30 30 30 30 30 30 28 28 24>,
				<3 126 126 126 126 126 126 126 126 126 126 126 126 126 126 126 126>,
				<1 30 30 30 30 30 28 28 0 0 0 0 0 0 0 0 0>,
				<1 10 18 18 18 18 18 18 18 18 18 18 18 18 26 26 26>,
				<1 30 30 30 30 30 30 30 30 28 28 24 24 0 0 0 0>,
				<5 126 126 126 126 126 126 126 126 126 126 126 126 126 126 126 126>;
			};
			r25 {
				channels = <132 132>;
				txs-delta = <0 0 0>;
				rates-cck = <126 126 126 126>;
				rates-ofdm = <0 0 0 0 33 33 33 33>;
				rates-mcs =
				<1 22 22 22 22 22 22 22 22 22 27>,
				<1 27 27 27 24 24 28 28 28 28 28>,
				<2 126 126 126 126 126 126 126 126 126 126>;
				rates-ru =
				<1 33 33 32 32 33 33 33 33 33 32 32 32>,
				<1 28 28 28 28 28 28 28 28 28 28 0 0>,
				<1 0 0 0 0 0 4 4 4 4 4 4 4>,
				<1 22 22 22 22 22 22 22 22 22 27 27 27>,
				<1 27 27 27 24 24 28 28 28 28 28 28 28>,
				<2 126 126 126 126 126 126 126 126 126 126 126 126>;
				rates-eht-ru =
				<1 33 33 32 32 33 33 33 33 33 32 32 32 32 0 0 0>,
				<1 28 28 28 28 28 28 28 28 28 28 0 0 0 30 30 30>,
				<1 0 0 0 0 0 4 4 4 4 4 4 4 4 4 4 4>,
				<1 22 22 22 22 22 22 22 22 22 27 27 27 27 27 27 27>,
				<1 27 27 27 24 24 28 28 28 28 28 28 28 28 28 28 24>,
				<3 126 126 126 126 126 126 126 126 126 126 126 126 126 126 126 126>,
				<1 30 30 30 30 30 28 28 0 0 0 0 0 0 0 0 0>,
				<1 4 16 16 16 16 16 16 16 16 16 16 16 16 22 22 22>,
				<1 30 30 30 30 30 30 30 30 28 28 24 24 0 0 0 0>,
				<5 126 126 126 126 126 126 126 126 126 126 126 126 126 126 126 126>;
			};
			r26 {
				channels = <136 136>;
				txs-delta = <0 0 0>;
				rates-cck = <126 126 126 126>;
				rates-ofdm = <0 0 0 0 31 31 31 31>;
				rates-mcs =
				<1 18 18 18 18 18 18 18 18 18 27>,
				<1 27 27 27 24 24 28 28 28 28 28>,
				<2 126 126 126 126 126 126 126 126 126 126>;
				rates-ru =
				<1 31 31 31 31 29 29 29 29 29 29 29 29>,
				<1 28 28 28 28 28 28 28 28 28 28 0 0>,
				<1 0 0 0 0 0 4 4 4 4 4 4 4>,
				<1 18 18 18 18 18 18 18 18 18 27 27 27>,
				<1 27 27 27 24 24 28 28 28 28 28 28 28>,
				<2 126 126 126 126 126 126 126 126 126 126 126 126>;
				rates-eht-ru =
				<1 31 31 31 31 29 29 29 29 29 29 29 29 29 0 0 0>,
				<1 28 28 28 28 28 28 28 28 28 28 0 0 0 30 30 30>,
				<1 0 0 0 0 0 4 4 4 4 4 4 4 4 4 4 4>,
				<1 18 18 18 18 18 18 18 18 18 27 27 27 27 27 27 27>,
				<1 27 27 27 24 24 28 28 28 28 28 28 28 28 28 28 24>,
				<3 126 126 126 126 126 126 126 126 126 126 126 126 126 126 126 126>,
				<1 30 30 30 30 30 28 28 0 0 0 0 0 0 0 0 0>,
				<1 4 12 12 12 12 12 12 12 12 12 12 12 12 18 18 18>,
				<1 30 30 30 30 30 30 30 30 28 28 24 24 0 0 0 0>,
				<5 126 126 126 126 126 126 126 126 126 126 126 126 126 126 126 126>;
			};
			r27 {
				channels = <140 140>;
				txs-delta = <0 0 0>;
				rates-cck = <126 126 126 126>;
				rates-ofdm = <0 0 0 0 27 27 27 27>;
				rates-mcs =
				<1 18 18 18 18 18 18 18 18 18 25>,
				<1 25 25 25 24 24 30 30 30 30 30>,
				<2 126 126 126 126 126 126 126 126 126 126>;
				rates-ru =
				<1 27 27 27 27 25 25 25 25 25 25 25 25>,
				<1 32 32 32 32 32 30 30 30 28 28 0 0>,
				<1 0 0 0 0 0 4 4 4 4 4 4 4>,
				<1 18 18 18 18 18 18 18 18 18 25 25 25>,
				<1 25 25 25 24 24 30 30 30 30 30 30 30>,
				<2 126 126 126 126 126 126 126 126 126 126 126 126>;
				rates-eht-ru =
				<1 27 27 27 27 25 25 25 25 25 25 25 25 25 0 0 0>,
				<1 32 32 32 32 32 30 30 30 28 28 0 0 0 30 30 30>,
				<1 0 0 0 0 0 4 4 4 4 4 4 4 4 4 4 4>,
				<1 18 18 18 18 18 18 18 18 18 25 25 25 25 25 25 25>,
				<1 25 25 25 24 24 30 30 30 30 30 30 30 30 28 28 24>,
				<3 126 126 126 126 126 126 126 126 126 126 126 126 126 126 126 126>,
				<1 30 30 30 30 30 28 28 0 0 0 0 0 0 0 0 0>,
				<1 4 12 12 12 12 12 12 12 12 12 12 12 12 18 18 18>,
				<1 30 30 30 30 30 30 30 30 28 28 24 24 0 0 0 0>,
				<5 126 126 126 126 126 126 126 126 126 126 126 126 126 126 126 126>;
			};
			r28 {
				channels = <144 144>;
				txs-delta = <0 0 0>;
				rates-cck = <126 126 126 126>;
				rates-ofdm = <0 0 0 0 32 32 32 32>;
				rates-mcs =
				<1 28 28 28 28 28 28 28 24 24 30>,
				<1 30 28 28 24 24 30 30 30 30 30>,
				<2 126 126 126 126 126 126 126 126 126 126>;
				rates-ru =
				<1 32 32 32 32 33 33 33 33 33 32 32 32>,
				<1 32 32 32 32 32 30 30 30 28 28 0 0>,
				<1 0 0 0 0 0 4 4 4 4 4 4 4>,
				<1 28 28 28 28 28 28 28 24 24 30 30 30>,
				<1 30 28 28 24 24 30 30 30 30 30 30 30>,
				<2 126 126 126 126 126 126 126 126 126 126 126 126>;
				rates-eht-ru =
				<1 32 32 32 32 33 33 33 33 33 32 32 32 32 0 0 0>,
				<1 32 32 32 32 32 30 30 30 28 28 0 0 0 30 30 30>,
				<1 0 0 0 0 0 4 4 4 4 4 4 4 4 4 4 4>,
				<1 28 28 28 28 28 28 28 24 24 30 30 30 30 30 30 30>,
				<1 30 28 28 24 24 30 30 30 30 30 30 30 30 28 28 24>,
				<3 126 126 126 126 126 126 126 126 126 126 126 126 126 126 126 126>,
				<1 30 30 30 30 30 28 28 0 0 0 0 0 0 0 0 0>,
				<1 4 24 24 24 24 24 24 24 24 24 24 24 24 28 28 28>,
				<1 30 30 30 30 30 30 30 30 28 28 24 24 0 0 0 0>,
				<5 126 126 126 126 126 126 126 126 126 126 126 126 126 126 126 126>;
			};
			r29 {
				channels = <149 161>;
				txs-delta = <0 0 0>;
				rates-cck = <126 126 126 126>;
				rates-ofdm = <0 0 0 0 33 33 33 33>;
				rates-mcs =
				<1 25 25 25 25 25 25 25 24 24 28>,
				<1 28 28 28 24 24 30 30 30 30 30>,
				<2 126 126 126 126 126 126 126 126 126 126>;
				rates-ru =
				<1 33 33 32 32 33 33 33 33 33 32 32 32>,
				<1 32 32 32 32 32 30 30 30 28 28 0 0>,
				<1 0 0 0 0 0 16 16 16 16 16 16 16>,
				<1 25 25 25 25 25 25 25 24 24 28 28 28>,
				<1 28 28 28 24 24 30 30 30 30 30 30 30>,
				<2 126 126 126 126 126 126 126 126 126 126 126 126>;
				rates-eht-ru =
				<1 33 33 32 32 33 33 33 33 33 32 32 32 32 0 0 0>,
				<1 32 32 32 32 32 30 30 30 28 28 0 0 0 30 30 30>,
				<1 0 0 0 0 0 16 16 16 16 16 16 16 16 16 16 16>,
				<1 25 25 25 25 25 25 25 24 24 28 28 28 28 28 28 28>,
				<1 28 28 28 24 24 30 30 30 30 30 30 30 30 28 28 24>,
				<3 126 126 126 126 126 126 126 126 126 126 126 126 126 126 126 126>,
				<1 30 30 30 30 30 28 28 0 0 0 0 0 0 0 0 0>,
				<1 16 33 20 20 20 20 20 20 20 20 20 20 20 25 25 25>,
				<1 30 30 30 30 30 30 30 30 28 28 24 24 0 0 0 0>,
				<5 126 126 126 126 126 126 126 126 126 126 126 126 126 126 126 126>;
			};
			r30 {
				channels = <165 165>;
				txs-delta = <0 0 0>;
				rates-cck = <126 126 126 126>;
				rates-ofdm = <0 0 0 0 33 33 33 33>;
				rates-mcs =
				<1 33 33 32 32 32 28 28 26 26 33>,
				<1 32 28 28 26 26 0 0 0 0 0>,
				<2 126 126 126 126 126 126 126 126 126 126>;
				rates-ru =
				<1 33 33 32 32 33 33 33 33 33 32 32 32>,
				<1 0 0 0 0 0 0 0 0 0 0 0 0>,
				<1 0 0 0 0 0 33 33 33 33 33 32 32>,
				<1 33 33 32 32 32 28 28 26 26 33 33 33>,
				<1 32 28 28 26 26 0 0 0 0 0 0 0>,
				<2 126 126 126 126 126 126 126 126 126 126 126 126>;
				rates-eht-ru =
				<1 33 33 32 32 33 33 33 33 33 32 32 32 32 0 0 0>,
				<1 0 0 0 0 0 0 0 0 0 0 0 0 0 0 0 0>,
				<1 0 0 0 0 0 33 33 33 33 33 32 32 32 28 28 26>,
				<1 33 33 32 32 32 28 28 26 26 33 33 33 33 33 32 32>,
				<1 32 28 28 26 26 0 0 0 0 0 0 0 0 0 0 0>,
				<3 126 126 126 126 126 126 126 126 126 126 126 126 126 126 126 126>,
				<1 0 0 0 0 0 0 0 0 0 0 0 0 0 0 0 0>,
				<1 26 33 33 33 33 33 32 32 32 28 28 26 26 33 33 33>,
				<1 0 0 0 0 0 0 0 0 0 0 0 0 0 0 0 0>,
				<5 126 126 126 126 126 126 126 126 126 126 126 126 126 126 126 126>;
			};
			r31 {
				channels = <169 169>;
				txs-delta = <0 0 0>;
				rates-cck = <126 126 126 126>;
				rates-ofdm = <0 0 0 0 0 0 0 0>;
				rates-mcs =
				<2 0 0 0 0 0 0 0 0 0 0>,
				<2 126 126 126 126 126 126 126 126 126 126>;
				rates-ru =
				<5 0 0 0 0 0 0 0 0 0 0 0 0>,
				<2 126 126 126 126 126 126 126 126 126 126 126 126>;
				rates-eht-ru =
				<5 0 0 0 0 0 0 0 0 0 0 0 0 0 0 0 0>,
				<3 126 126 126 126 126 126 126 126 126 126 126 126 126 126 126 126>,
				<3 0 0 0 0 0 0 0 0 0 0 0 0 0 0 0 0>,
				<5 126 126 126 126 126 126 126 126 126 126 126 126 126 126 126 126>;
			};
			r32 {
				channels = <173 173>;
				txs-delta = <0 0 0>;
				rates-cck = <126 126 126 126>;
				rates-ofdm = <0 0 0 0 0 0 0 0>;
				rates-mcs =
				<2 0 0 0 0 0 0 0 0 0 0>,
				<2 126 126 126 126 126 126 126 126 126 126>;
				rates-ru =
				<5 0 0 0 0 0 0 0 0 0 0 0 0>,
				<2 126 126 126 126 126 126 126 126 126 126 126 126>;
				rates-eht-ru =
				<5 0 0 0 0 0 0 0 0 0 0 0 0 0 0 0 0>,
				<3 126 126 126 126 126 126 126 126 126 126 126 126 126 126 126 126>,
				<3 0 0 0 0 0 0 0 0 0 0 0 0 0 0 0 0>,
				<5 126 126 126 126 126 126 126 126 126 126 126 126 126 126 126 126>;
			};
			r33 {
				channels = <177 177>;
				txs-delta = <0 0 0>;
				rates-cck = <126 126 126 126>;
				rates-ofdm = <0 0 0 0 0 0 0 0>;
				rates-mcs =
				<2 0 0 0 0 0 0 0 0 0 0>,
				<2 126 126 126 126 126 126 126 126 126 126>;
				rates-ru =
				<5 0 0 0 0 0 0 0 0 0 0 0 0>,
				<2 126 126 126 126 126 126 126 126 126 126 126 126>;
				rates-eht-ru =
				<5 0 0 0 0 0 0 0 0 0 0 0 0 0 0 0 0>,
				<3 126 126 126 126 126 126 126 126 126 126 126 126 126 126 126 126>,
				<3 0 0 0 0 0 0 0 0 0 0 0 0 0 0 0 0>,
				<5 126 126 126 126 126 126 126 126 126 126 126 126 126 126 126 126>;
			};
			r34 {
				channels = <181 181>;
				txs-delta = <0 0 0>;
				rates-cck = <126 126 126 126>;
				rates-ofdm = <0 0 0 0 0 0 0 0>;
				rates-mcs =
				<2 0 0 0 0 0 0 0 0 0 0>,
				<2 126 126 126 126 126 126 126 126 126 126>;
				rates-ru =
				<5 0 0 0 0 0 0 0 0 0 0 0 0>,
				<2 126 126 126 126 126 126 126 126 126 126 126 126>;
				rates-eht-ru =
				<5 0 0 0 0 0 0 0 0 0 0 0 0 0 0 0 0>,
				<3 126 126 126 126 126 126 126 126 126 126 126 126 126 126 126 126>,
				<3 0 0 0 0 0 0 0 0 0 0 0 0 0 0 0 0>,
				<5 126 126 126 126 126 126 126 126 126 126 126 126 126 126 126 126>;
			};
		};
	};
	etsi {
		regdomain = "etsi";
		txpower-2g {
			r0 {
				channels = <1 2>;
				txs-delta = <0 0 0>;
				rates-cck = <23 23 23 23>;
				rates-ofdm = <26 26 26 26 26 26 26 26>;
				rates-mcs =
				<1 24 24 24 24 24 26 26 26 26 26>,
				<1 26 0 0 0 0 0 0 0 0 0>,
				<2 126 126 126 126 126 126 126 126 126 126>;
				rates-ru =
				<1 26 26 26 26 26 26 26 26 26 0 0 0>,
				<1 0 0 0 0 0 0 0 0 0 0 0 0>,
				<1 0 13 13 13 13 13 13 13 13 13 13 13>,
				<1 24 24 24 24 24 26 26 26 26 26 26 26>,
				<1 26 0 0 0 0 0 0 0 0 0 0 0>,
				<2 126 126 126 126 126 126 126 126 126 126 126 126>;
				rates-eht-ru =
				<1 26 26 26 26 26 26 26 26 26 0 0 0 0 0 0 0>,
				<1 0 0 0 0 0 0 0 0 0 0 0 0 0 0 0 0>,
				<1 0 13 13 13 13 13 13 13 13 13 13 13 13 18 18 18>,
				<1 24 24 24 24 24 26 26 26 26 26 26 26 26 26 26 26>,
				<1 26 0 0 0 0 0 0 0 0 0 0 0 0 0 0 0>,
				<3 126 126 126 126 126 126 126 126 126 126 126 126 126 126 126 126>,
				<1 0 0 0 0 0 0 0 0 0 0 0 0 0 0 0 0>,
				<1 18 18 18 18 18 18 18 18 18 24 24 24 24 24 24 24>,
				<1 0 0 0 0 0 0 0 0 0 0 0 0 0 0 0 0>,
				<5 126 126 126 126 126 126 126 126 126 126 126 126 126 126 126 126>;
			};
			r1 {
				channels = <3 11>;
				txs-delta = <0 0 0>;
				rates-cck = <23 23 23 23>;
				rates-ofdm = <26 26 26 26 26 26 26 26>;
				rates-mcs =
				<1 24 24 24 24 24 26 26 26 26 26>,
				<1 26 26 26 26 26 26 26 26 26 26>,
				<2 126 126 126 126 126 126 126 126 126 126>;
				rates-ru =
				<1 26 26 26 26 26 26 26 26 26 0 0 0>,
				<1 26 26 26 26 26 26 0 0 0 0 0 0>,
				<1 0 13 13 13 13 13 13 13 13 13 13 13>,
				<1 24 24 24 24 24 26 26 26 26 26 26 26>,
				<1 26 26 26 26 26 26 26 26 26 26 26 26>,
				<2 126 126 126 126 126 126 126 126 126 126 126 126>;
				rates-eht-ru =
				<1 26 26 26 26 26 26 26 26 26 0 0 0 26 26 26 26>,
				<1 26 26 26 26 26 26 0 0 0 0 0 0 0 0 0 0>,
				<1 0 13 13 13 13 13 13 13 13 13 13 13 13 18 18 18>,
				<1 24 24 24 24 24 26 26 26 26 26 26 26 26 26 26 26>,
				<1 26 26 26 26 26 26 26 26 26 26 26 26 26 0 0 0>,
				<3 126 126 126 126 126 126 126 126 126 126 126 126 126 126 126 126>,
				<1 0 0 0 0 0 0 0 0 0 0 0 0 0 0 0 0>,
				<1 18 18 18 18 18 18 18 18 18 24 24 24 24 24 24 24>,
				<1 0 0 0 0 0 0 0 0 0 0 0 0 0 0 0 0>,
				<5 126 126 126 126 126 126 126 126 126 126 126 126 126 126 126 126>;
			};
			r2 {
				channels = <12 12>;
				txs-delta = <0 0 0>;
				rates-cck = <23 23 23 23>;
				rates-ofdm = <26 26 26 26 26 26 26 26>;
				rates-mcs =
				<1 24 24 24 24 24 26 26 26 26 26>,
				<1 26 0 0 0 0 0 0 0 0 0>,
				<2 126 126 126 126 126 126 126 126 126 126>;
				rates-ru =
				<1 26 26 26 26 26 26 26 26 26 0 0 0>,
				<1 0 0 0 0 0 0 0 0 0 0 0 0>,
				<1 0 13 13 13 13 13 13 13 13 13 13 13>,
				<1 24 24 24 24 24 26 26 26 26 26 26 26>,
				<1 26 0 0 0 0 0 0 0 0 0 0 0>,
				<2 126 126 126 126 126 126 126 126 126 126 126 126>;
				rates-eht-ru =
				<1 26 26 26 26 26 26 26 26 26 0 0 0 0 0 0 0>,
				<1 0 0 0 0 0 0 0 0 0 0 0 0 0 0 0 0>,
				<1 0 13 13 13 13 13 13 13 13 13 13 13 13 18 18 18>,
				<1 24 24 24 24 24 26 26 26 26 26 26 26 26 26 26 26>,
				<1 26 0 0 0 0 0 0 0 0 0 0 0 0 0 0 0>,
				<3 126 126 126 126 126 126 126 126 126 126 126 126 126 126 126 126>,
				<1 0 0 0 0 0 0 0 0 0 0 0 0 0 0 0 0>,
				<1 18 18 18 18 18 18 18 18 18 24 24 24 24 24 24 24>,
				<1 0 0 0 0 0 0 0 0 0 0 0 0 0 0 0 0>,
				<5 126 126 126 126 126 126 126 126 126 126 126 126 126 126 126 126>;
			};
			r3 {
				channels = <13 13>;
				txs-delta = <0 0 0>;
				rates-cck = <23 23 23 23>;
				rates-ofdm = <26 26 26 26 26 26 26 26>;
				rates-mcs =
				<1 24 24 24 24 24 26 26 26 26 26>,
				<1 26 0 0 0 0 0 0 0 0 0>,
				<2 126 126 126 126 126 126 126 126 126 126>;
				rates-ru =
				<1 26 26 26 26 26 26 26 26 26 0 0 0>,
				<1 0 0 0 0 0 0 0 0 0 0 0 0>,
				<1 0 13 13 13 13 13 13 13 13 13 13 13>,
				<1 24 24 24 24 24 26 26 26 26 26 26 26>,
				<1 26 0 0 0 0 0 0 0 0 0 0 0>,
				<2 126 126 126 126 126 126 126 126 126 126 126 126>;
				rates-eht-ru =
				<1 26 26 26 26 26 26 26 26 26 0 0 0 0 0 0 0>,
				<1 0 0 0 0 0 0 0 0 0 0 0 0 0 0 0 0>,
				<1 0 13 13 13 13 13 13 13 13 13 13 13 13 18 18 18>,
				<1 24 24 24 24 24 26 26 26 26 26 26 26 26 26 26 26>,
				<1 26 0 0 0 0 0 0 0 0 0 0 0 0 0 0 0>,
				<3 126 126 126 126 126 126 126 126 126 126 126 126 126 126 126 126>,
				<1 0 0 0 0 0 0 0 0 0 0 0 0 0 0 0 0>,
				<1 18 18 18 18 18 18 18 18 18 24 24 24 24 24 24 24>,
				<1 0 0 0 0 0 0 0 0 0 0 0 0 0 0 0 0>,
				<5 126 126 126 126 126 126 126 126 126 126 126 126 126 126 126 126>;
			};
			r4 {
				channels = <14 14>;
				txs-delta = <0 0 0>;
				rates-cck = <0 0 0 0>;
				rates-ofdm = <0 0 0 0 0 0 0 0>;
				rates-mcs =
				<2 0 0 0 0 0 0 0 0 0 0>,
				<2 126 126 126 126 126 126 126 126 126 126>;
				rates-ru =
				<5 0 0 0 0 0 0 0 0 0 0 0 0>,
				<2 126 126 126 126 126 126 126 126 126 126 126 126>;
				rates-eht-ru =
				<5 0 0 0 0 0 0 0 0 0 0 0 0 0 0 0 0>,
				<3 126 126 126 126 126 126 126 126 126 126 126 126 126 126 126 126>,
				<3 0 0 0 0 0 0 0 0 0 0 0 0 0 0 0 0>,
				<5 126 126 126 126 126 126 126 126 126 126 126 126 126 126 126 126>;
			};
		};
		txpower-5g {
			r0 {
				channels = <184 196>;
				txs-delta = <0 0 0>;
				rates-cck = <126 126 126 126>;
				rates-ofdm = <0 0 0 0 0 0 0 0>;
				rates-mcs =
				<2 0 0 0 0 0 0 0 0 0 0>,
				<2 126 126 126 126 126 126 126 126 126 126>;
				rates-ru =
				<5 0 0 0 0 0 0 0 0 0 0 0 0>,
				<2 126 126 126 126 126 126 126 126 126 126 126 126>;
				rates-eht-ru =
				<5 0 0 0 0 0 0 0 0 0 0 0 0 0 0 0 0>,
				<3 126 126 126 126 126 126 126 126 126 126 126 126 126 126 126 126>,
				<3 0 0 0 0 0 0 0 0 0 0 0 0 0 0 0 0>,
				<5 126 126 126 126 126 126 126 126 126 126 126 126 126 126 126 126>;
			};
			r1 {
				channels = <8 16>;
				txs-delta = <0 0 0>;
				rates-cck = <126 126 126 126>;
				rates-ofdm = <0 0 0 0 0 0 0 0>;
				rates-mcs =
				<2 0 0 0 0 0 0 0 0 0 0>,
				<2 126 126 126 126 126 126 126 126 126 126>;
				rates-ru =
				<5 0 0 0 0 0 0 0 0 0 0 0 0>,
				<2 126 126 126 126 126 126 126 126 126 126 126 126>;
				rates-eht-ru =
				<5 0 0 0 0 0 0 0 0 0 0 0 0 0 0 0 0>,
				<3 126 126 126 126 126 126 126 126 126 126 126 126 126 126 126 126>,
				<3 0 0 0 0 0 0 0 0 0 0 0 0 0 0 0 0>,
				<5 126 126 126 126 126 126 126 126 126 126 126 126 126 126 126 126>;
			};
			r2 {
				channels = <36 64>;
				txs-delta = <0 0 0>;
				rates-cck = <126 126 126 126>;
				rates-ofdm = <0 0 0 0 24 24 24 24>;
				rates-mcs =
				<1 21 21 21 21 21 21 21 21 21 26>,
				<1 26 26 26 24 24 28 28 28 28 28>,
				<2 126 126 126 126 126 126 126 126 126 126>;
				rates-ru =
				<1 24 24 24 24 26 26 26 26 26 26 26 26>,
				<1 28 28 28 28 28 28 28 28 28 28 0 0>,
				<1 0 0 0 0 0 9 9 9 9 9 9 9>,
				<1 21 21 21 21 21 21 21 21 21 26 26 26>,
				<1 26 26 26 24 24 28 28 28 28 28 28 28>,
				<2 126 126 126 126 126 126 126 126 126 126 126 126>;
				rates-eht-ru =
				<1 24 24 24 24 26 26 26 26 26 26 26 26 26 0 0 0>,
				<1 28 28 28 28 28 28 28 28 28 28 0 0 0 28 28 28>,
				<1 0 0 0 0 0 9 9 9 9 9 9 9 9 9 9 9>,
				<1 21 21 21 21 21 21 21 21 21 26 26 26 26 26 26 26>,
				<1 26 26 26 24 24 28 28 28 28 28 28 28 28 28 28 24>,
				<3 126 126 126 126 126 126 126 126 126 126 126 126 126 126 126 126>,
				<1 28 28 28 28 28 28 28 0 0 0 0 0 0 0 0 0>,
				<1 9 15 15 15 15 15 15 15 15 15 15 15 15 21 21 21>,
				<1 28 28 28 28 28 28 28 28 28 28 24 24 0 0 0 0>,
				<5 126 126 126 126 126 126 126 126 126 126 126 126 126 126 126 126>;
			};
			r3 {
				channels = <68 68>;
				txs-delta = <0 0 0>;
				rates-cck = <126 126 126 126>;
				rates-ofdm = <0 0 0 0 0 0 0 0>;
				rates-mcs =
				<2 0 0 0 0 0 0 0 0 0 0>,
				<2 126 126 126 126 126 126 126 126 126 126>;
				rates-ru =
				<5 0 0 0 0 0 0 0 0 0 0 0 0>,
				<2 126 126 126 126 126 126 126 126 126 126 126 126>;
				rates-eht-ru =
				<5 0 0 0 0 0 0 0 0 0 0 0 0 0 0 0 0>,
				<3 126 126 126 126 126 126 126 126 126 126 126 126 126 126 126 126>,
				<3 0 0 0 0 0 0 0 0 0 0 0 0 0 0 0 0>,
				<5 126 126 126 126 126 126 126 126 126 126 126 126 126 126 126 126>;
			};
			r4 {
				channels = <72 72>;
				txs-delta = <0 0 0>;
				rates-cck = <126 126 126 126>;
				rates-ofdm = <0 0 0 0 0 0 0 0>;
				rates-mcs =
				<2 0 0 0 0 0 0 0 0 0 0>,
				<2 126 126 126 126 126 126 126 126 126 126>;
				rates-ru =
				<5 0 0 0 0 0 0 0 0 0 0 0 0>,
				<2 126 126 126 126 126 126 126 126 126 126 126 126>;
				rates-eht-ru =
				<5 0 0 0 0 0 0 0 0 0 0 0 0 0 0 0 0>,
				<3 126 126 126 126 126 126 126 126 126 126 126 126 126 126 126 126>,
				<3 0 0 0 0 0 0 0 0 0 0 0 0 0 0 0 0>,
				<5 126 126 126 126 126 126 126 126 126 126 126 126 126 126 126 126>;
			};
			r5 {
				channels = <76 76>;
				txs-delta = <0 0 0>;
				rates-cck = <126 126 126 126>;
				rates-ofdm = <0 0 0 0 0 0 0 0>;
				rates-mcs =
				<2 0 0 0 0 0 0 0 0 0 0>,
				<2 126 126 126 126 126 126 126 126 126 126>;
				rates-ru =
				<5 0 0 0 0 0 0 0 0 0 0 0 0>,
				<2 126 126 126 126 126 126 126 126 126 126 126 126>;
				rates-eht-ru =
				<5 0 0 0 0 0 0 0 0 0 0 0 0 0 0 0 0>,
				<3 126 126 126 126 126 126 126 126 126 126 126 126 126 126 126 126>,
				<3 0 0 0 0 0 0 0 0 0 0 0 0 0 0 0 0>,
				<5 126 126 126 126 126 126 126 126 126 126 126 126 126 126 126 126>;
			};
			r6 {
				channels = <80 80>;
				txs-delta = <0 0 0>;
				rates-cck = <126 126 126 126>;
				rates-ofdm = <0 0 0 0 0 0 0 0>;
				rates-mcs =
				<2 0 0 0 0 0 0 0 0 0 0>,
				<2 126 126 126 126 126 126 126 126 126 126>;
				rates-ru =
				<5 0 0 0 0 0 0 0 0 0 0 0 0>,
				<2 126 126 126 126 126 126 126 126 126 126 126 126>;
				rates-eht-ru =
				<5 0 0 0 0 0 0 0 0 0 0 0 0 0 0 0 0>,
				<3 126 126 126 126 126 126 126 126 126 126 126 126 126 126 126 126>,
				<3 0 0 0 0 0 0 0 0 0 0 0 0 0 0 0 0>,
				<5 126 126 126 126 126 126 126 126 126 126 126 126 126 126 126 126>;
			};
			r7 {
				channels = <84 84>;
				txs-delta = <0 0 0>;
				rates-cck = <126 126 126 126>;
				rates-ofdm = <0 0 0 0 0 0 0 0>;
				rates-mcs =
				<2 0 0 0 0 0 0 0 0 0 0>,
				<2 126 126 126 126 126 126 126 126 126 126>;
				rates-ru =
				<5 0 0 0 0 0 0 0 0 0 0 0 0>,
				<2 126 126 126 126 126 126 126 126 126 126 126 126>;
				rates-eht-ru =
				<5 0 0 0 0 0 0 0 0 0 0 0 0 0 0 0 0>,
				<3 126 126 126 126 126 126 126 126 126 126 126 126 126 126 126 126>,
				<3 0 0 0 0 0 0 0 0 0 0 0 0 0 0 0 0>,
				<5 126 126 126 126 126 126 126 126 126 126 126 126 126 126 126 126>;
			};
			r8 {
				channels = <88 88>;
				txs-delta = <0 0 0>;
				rates-cck = <126 126 126 126>;
				rates-ofdm = <0 0 0 0 0 0 0 0>;
				rates-mcs =
				<2 0 0 0 0 0 0 0 0 0 0>,
				<2 126 126 126 126 126 126 126 126 126 126>;
				rates-ru =
				<5 0 0 0 0 0 0 0 0 0 0 0 0>,
				<2 126 126 126 126 126 126 126 126 126 126 126 126>;
				rates-eht-ru =
				<5 0 0 0 0 0 0 0 0 0 0 0 0 0 0 0 0>,
				<3 126 126 126 126 126 126 126 126 126 126 126 126 126 126 126 126>,
				<3 0 0 0 0 0 0 0 0 0 0 0 0 0 0 0 0>,
				<5 126 126 126 126 126 126 126 126 126 126 126 126 126 126 126 126>;
			};
			r9 {
				channels = <92 92>;
				txs-delta = <0 0 0>;
				rates-cck = <126 126 126 126>;
				rates-ofdm = <0 0 0 0 0 0 0 0>;
				rates-mcs =
				<2 0 0 0 0 0 0 0 0 0 0>,
				<2 126 126 126 126 126 126 126 126 126 126>;
				rates-ru =
				<5 0 0 0 0 0 0 0 0 0 0 0 0>,
				<2 126 126 126 126 126 126 126 126 126 126 126 126>;
				rates-eht-ru =
				<5 0 0 0 0 0 0 0 0 0 0 0 0 0 0 0 0>,
				<3 126 126 126 126 126 126 126 126 126 126 126 126 126 126 126 126>,
				<3 0 0 0 0 0 0 0 0 0 0 0 0 0 0 0 0>,
				<5 126 126 126 126 126 126 126 126 126 126 126 126 126 126 126 126>;
			};
			r10 {
				channels = <96 96>;
				txs-delta = <0 0 0>;
				rates-cck = <126 126 126 126>;
				rates-ofdm = <0 0 0 0 0 0 0 0>;
				rates-mcs =
				<2 0 0 0 0 0 0 0 0 0 0>,
				<2 126 126 126 126 126 126 126 126 126 126>;
				rates-ru =
				<5 0 0 0 0 0 0 0 0 0 0 0 0>,
				<2 126 126 126 126 126 126 126 126 126 126 126 126>;
				rates-eht-ru =
				<5 0 0 0 0 0 0 0 0 0 0 0 0 0 0 0 0>,
				<3 126 126 126 126 126 126 126 126 126 126 126 126 126 126 126 126>,
				<3 0 0 0 0 0 0 0 0 0 0 0 0 0 0 0 0>,
				<5 126 126 126 126 126 126 126 126 126 126 126 126 126 126 126 126>;
			};
			r11 {
				channels = <100 100>;
				txs-delta = <0 0 0>;
				rates-cck = <126 126 126 126>;
				rates-ofdm = <0 0 0 0 24 24 24 24>;
				rates-mcs =
				<1 21 21 21 21 21 21 21 21 21 26>,
				<1 26 26 26 24 24 28 28 28 28 28>,
				<2 126 126 126 126 126 126 126 126 126 126>;
				rates-ru =
				<1 24 24 24 24 26 26 26 26 26 26 26 26>,
				<1 28 28 28 28 28 28 28 28 28 28 0 0>,
				<1 0 0 0 0 0 9 9 9 9 9 9 9>,
				<1 21 21 21 21 21 21 21 21 21 26 26 26>,
				<1 26 26 26 24 24 28 28 28 28 28 28 28>,
				<2 126 126 126 126 126 126 126 126 126 126 126 126>;
				rates-eht-ru =
				<1 24 24 24 24 26 26 26 26 26 26 26 26 26 0 0 0>,
				<1 28 28 28 28 28 28 28 28 28 28 0 0 0 28 28 28>,
				<1 0 0 0 0 0 9 9 9 9 9 9 9 9 9 9 9>,
				<1 21 21 21 21 21 21 21 21 21 26 26 26 26 26 26 26>,
				<1 26 26 26 24 24 28 28 28 28 28 28 28 28 28 28 24>,
				<3 126 126 126 126 126 126 126 126 126 126 126 126 126 126 126 126>,
				<1 28 28 28 28 28 28 28 0 0 0 0 0 0 0 0 0>,
				<1 9 15 15 15 15 15 15 15 15 15 15 15 15 21 21 21>,
				<1 28 28 28 28 28 28 28 28 28 28 24 24 0 0 0 0>,
				<5 126 126 126 126 126 126 126 126 126 126 126 126 126 126 126 126>;
			};
			r12 {
				channels = <104 104>;
				txs-delta = <0 0 0>;
				rates-cck = <126 126 126 126>;
				rates-ofdm = <0 0 0 0 24 24 24 24>;
				rates-mcs =
				<1 21 21 21 21 21 21 21 21 21 26>,
				<1 26 26 26 24 24 28 28 28 28 28>,
				<2 126 126 126 126 126 126 126 126 126 126>;
				rates-ru =
				<1 24 24 24 24 26 26 26 26 26 26 26 26>,
				<1 28 28 28 28 28 28 28 28 28 28 0 0>,
				<1 0 0 0 0 0 9 9 9 9 9 9 9>,
				<1 21 21 21 21 21 21 21 21 21 26 26 26>,
				<1 26 26 26 24 24 28 28 28 28 28 28 28>,
				<2 126 126 126 126 126 126 126 126 126 126 126 126>;
				rates-eht-ru =
				<1 24 24 24 24 26 26 26 26 26 26 26 26 26 0 0 0>,
				<1 28 28 28 28 28 28 28 28 28 28 0 0 0 28 28 28>,
				<1 0 0 0 0 0 9 9 9 9 9 9 9 9 9 9 9>,
				<1 21 21 21 21 21 21 21 21 21 26 26 26 26 26 26 26>,
				<1 26 26 26 24 24 28 28 28 28 28 28 28 28 28 28 24>,
				<3 126 126 126 126 126 126 126 126 126 126 126 126 126 126 126 126>,
				<1 28 28 28 28 28 28 28 0 0 0 0 0 0 0 0 0>,
				<1 9 15 15 15 15 15 15 15 15 15 15 15 15 21 21 21>,
				<1 28 28 28 28 28 28 28 28 28 28 24 24 0 0 0 0>,
				<5 126 126 126 126 126 126 126 126 126 126 126 126 126 126 126 126>;
			};
			r13 {
				channels = <108 108>;
				txs-delta = <0 0 0>;
				rates-cck = <126 126 126 126>;
				rates-ofdm = <0 0 0 0 24 24 24 24>;
				rates-mcs =
				<1 21 21 21 21 21 21 21 21 21 26>,
				<1 26 26 26 24 24 28 28 28 28 28>,
				<2 126 126 126 126 126 126 126 126 126 126>;
				rates-ru =
				<1 24 24 24 24 26 26 26 26 26 26 26 26>,
				<1 28 28 28 28 28 28 28 28 28 28 0 0>,
				<1 0 0 0 0 0 9 9 9 9 9 9 9>,
				<1 21 21 21 21 21 21 21 21 21 26 26 26>,
				<1 26 26 26 24 24 28 28 28 28 28 28 28>,
				<2 126 126 126 126 126 126 126 126 126 126 126 126>;
				rates-eht-ru =
				<1 24 24 24 24 26 26 26 26 26 26 26 26 26 0 0 0>,
				<1 28 28 28 28 28 28 28 28 28 28 0 0 0 28 28 28>,
				<1 0 0 0 0 0 9 9 9 9 9 9 9 9 9 9 9>,
				<1 21 21 21 21 21 21 21 21 21 26 26 26 26 26 26 26>,
				<1 26 26 26 24 24 28 28 28 28 28 28 28 28 28 28 24>,
				<3 126 126 126 126 126 126 126 126 126 126 126 126 126 126 126 126>,
				<1 28 28 28 28 28 28 28 0 0 0 0 0 0 0 0 0>,
				<1 9 15 15 15 15 15 15 15 15 15 15 15 15 21 21 21>,
				<1 28 28 28 28 28 28 28 28 28 28 24 24 0 0 0 0>,
				<5 126 126 126 126 126 126 126 126 126 126 126 126 126 126 126 126>;
			};
			r14 {
				channels = <112 112>;
				txs-delta = <0 0 0>;
				rates-cck = <126 126 126 126>;
				rates-ofdm = <0 0 0 0 24 24 24 24>;
				rates-mcs =
				<1 21 21 21 21 21 21 21 21 21 26>,
				<1 26 26 26 24 24 28 28 28 28 28>,
				<2 126 126 126 126 126 126 126 126 126 126>;
				rates-ru =
				<1 24 24 24 24 26 26 26 26 26 26 26 26>,
				<1 28 28 28 28 28 28 28 28 28 28 0 0>,
				<1 0 0 0 0 0 9 9 9 9 9 9 9>,
				<1 21 21 21 21 21 21 21 21 21 26 26 26>,
				<1 26 26 26 24 24 28 28 28 28 28 28 28>,
				<2 126 126 126 126 126 126 126 126 126 126 126 126>;
				rates-eht-ru =
				<1 24 24 24 24 26 26 26 26 26 26 26 26 26 0 0 0>,
				<1 28 28 28 28 28 28 28 28 28 28 0 0 0 28 28 28>,
				<1 0 0 0 0 0 9 9 9 9 9 9 9 9 9 9 9>,
				<1 21 21 21 21 21 21 21 21 21 26 26 26 26 26 26 26>,
				<1 26 26 26 24 24 28 28 28 28 28 28 28 28 28 28 24>,
				<3 126 126 126 126 126 126 126 126 126 126 126 126 126 126 126 126>,
				<1 28 28 28 28 28 28 28 0 0 0 0 0 0 0 0 0>,
				<1 9 15 15 15 15 15 15 15 15 15 15 15 15 21 21 21>,
				<1 28 28 28 28 28 28 28 28 28 28 24 24 0 0 0 0>,
				<5 126 126 126 126 126 126 126 126 126 126 126 126 126 126 126 126>;
			};
			r15 {
				channels = <116 116>;
				txs-delta = <0 0 0>;
				rates-cck = <126 126 126 126>;
				rates-ofdm = <0 0 0 0 24 24 24 24>;
				rates-mcs =
				<1 21 21 21 21 21 21 21 21 21 26>,
				<1 26 26 26 24 24 28 28 28 28 28>,
				<2 126 126 126 126 126 126 126 126 126 126>;
				rates-ru =
				<1 24 24 24 24 26 26 26 26 26 26 26 26>,
				<1 28 28 28 28 28 28 28 28 28 28 0 0>,
				<1 0 0 0 0 0 9 9 9 9 9 9 9>,
				<1 21 21 21 21 21 21 21 21 21 26 26 26>,
				<1 26 26 26 24 24 28 28 28 28 28 28 28>,
				<2 126 126 126 126 126 126 126 126 126 126 126 126>;
				rates-eht-ru =
				<1 24 24 24 24 26 26 26 26 26 26 26 26 26 0 0 0>,
				<1 28 28 28 28 28 28 28 28 28 28 0 0 0 28 28 28>,
				<1 0 0 0 0 0 9 9 9 9 9 9 9 9 9 9 9>,
				<1 21 21 21 21 21 21 21 21 21 26 26 26 26 26 26 26>,
				<1 26 26 26 24 24 28 28 28 28 28 28 28 28 28 28 24>,
				<3 126 126 126 126 126 126 126 126 126 126 126 126 126 126 126 126>,
				<1 28 28 28 28 28 28 28 0 0 0 0 0 0 0 0 0>,
				<1 9 15 15 15 15 15 15 15 15 15 15 15 15 21 21 21>,
				<1 28 28 28 28 28 28 28 28 28 28 24 24 0 0 0 0>,
				<5 126 126 126 126 126 126 126 126 126 126 126 126 126 126 126 126>;
			};
			r16 {
				channels = <120 120>;
				txs-delta = <0 0 0>;
				rates-cck = <126 126 126 126>;
				rates-ofdm = <0 0 0 0 24 24 24 24>;
				rates-mcs =
				<1 21 21 21 21 21 21 21 21 21 26>,
				<1 26 26 26 24 24 28 28 28 28 28>,
				<2 126 126 126 126 126 126 126 126 126 126>;
				rates-ru =
				<1 24 24 24 24 26 26 26 26 26 26 26 26>,
				<1 28 28 28 28 28 28 28 28 28 28 0 0>,
				<1 0 0 0 0 0 9 9 9 9 9 9 9>,
				<1 21 21 21 21 21 21 21 21 21 26 26 26>,
				<1 26 26 26 24 24 28 28 28 28 28 28 28>,
				<2 126 126 126 126 126 126 126 126 126 126 126 126>;
				rates-eht-ru =
				<1 24 24 24 24 26 26 26 26 26 26 26 26 26 0 0 0>,
				<1 28 28 28 28 28 28 28 28 28 28 0 0 0 28 28 28>,
				<1 0 0 0 0 0 9 9 9 9 9 9 9 9 9 9 9>,
				<1 21 21 21 21 21 21 21 21 21 26 26 26 26 26 26 26>,
				<1 26 26 26 24 24 28 28 28 28 28 28 28 28 28 28 24>,
				<3 126 126 126 126 126 126 126 126 126 126 126 126 126 126 126 126>,
				<1 28 28 28 28 28 28 28 0 0 0 0 0 0 0 0 0>,
				<1 9 15 15 15 15 15 15 15 15 15 15 15 15 21 21 21>,
				<1 28 28 28 28 28 28 28 28 28 28 24 24 0 0 0 0>,
				<5 126 126 126 126 126 126 126 126 126 126 126 126 126 126 126 126>;
			};
			r17 {
				channels = <124 124>;
				txs-delta = <0 0 0>;
				rates-cck = <126 126 126 126>;
				rates-ofdm = <0 0 0 0 24 24 24 24>;
				rates-mcs =
				<1 21 21 21 21 21 21 21 21 21 26>,
				<1 26 26 26 24 24 28 28 28 28 28>,
				<2 126 126 126 126 126 126 126 126 126 126>;
				rates-ru =
				<1 24 24 24 24 26 26 26 26 26 26 26 26>,
				<1 28 28 28 28 28 28 28 28 28 28 0 0>,
				<1 0 0 0 0 0 9 9 9 9 9 9 9>,
				<1 21 21 21 21 21 21 21 21 21 26 26 26>,
				<1 26 26 26 24 24 28 28 28 28 28 28 28>,
				<2 126 126 126 126 126 126 126 126 126 126 126 126>;
				rates-eht-ru =
				<1 24 24 24 24 26 26 26 26 26 26 26 26 26 0 0 0>,
				<1 28 28 28 28 28 28 28 28 28 28 0 0 0 28 28 28>,
				<1 0 0 0 0 0 9 9 9 9 9 9 9 9 9 9 9>,
				<1 21 21 21 21 21 21 21 21 21 26 26 26 26 26 26 26>,
				<1 26 26 26 24 24 28 28 28 28 28 28 28 28 28 28 24>,
				<3 126 126 126 126 126 126 126 126 126 126 126 126 126 126 126 126>,
				<1 28 28 28 28 28 28 28 0 0 0 0 0 0 0 0 0>,
				<1 9 15 15 15 15 15 15 15 15 15 15 15 15 21 21 21>,
				<1 28 28 28 28 28 28 28 28 28 28 24 24 0 0 0 0>,
				<5 126 126 126 126 126 126 126 126 126 126 126 126 126 126 126 126>;
			};
			r18 {
				channels = <128 128>;
				txs-delta = <0 0 0>;
				rates-cck = <126 126 126 126>;
				rates-ofdm = <0 0 0 0 24 24 24 24>;
				rates-mcs =
				<1 21 21 21 21 21 21 21 21 21 26>,
				<1 26 26 26 24 24 28 28 28 28 28>,
				<2 126 126 126 126 126 126 126 126 126 126>;
				rates-ru =
				<1 24 24 24 24 26 26 26 26 26 26 26 26>,
				<1 28 28 28 28 28 28 28 28 28 28 0 0>,
				<1 0 0 0 0 0 9 9 9 9 9 9 9>,
				<1 21 21 21 21 21 21 21 21 21 26 26 26>,
				<1 26 26 26 24 24 28 28 28 28 28 28 28>,
				<2 126 126 126 126 126 126 126 126 126 126 126 126>;
				rates-eht-ru =
				<1 24 24 24 24 26 26 26 26 26 26 26 26 26 0 0 0>,
				<1 28 28 28 28 28 28 28 28 28 28 0 0 0 28 28 28>,
				<1 0 0 0 0 0 9 9 9 9 9 9 9 9 9 9 9>,
				<1 21 21 21 21 21 21 21 21 21 26 26 26 26 26 26 26>,
				<1 26 26 26 24 24 28 28 28 28 28 28 28 28 28 28 24>,
				<3 126 126 126 126 126 126 126 126 126 126 126 126 126 126 126 126>,
				<1 28 28 28 28 28 28 28 0 0 0 0 0 0 0 0 0>,
				<1 9 15 15 15 15 15 15 15 15 15 15 15 15 21 21 21>,
				<1 28 28 28 28 28 28 28 28 28 28 24 24 0 0 0 0>,
				<5 126 126 126 126 126 126 126 126 126 126 126 126 126 126 126 126>;
			};
			r19 {
				channels = <132 136>;
				txs-delta = <0 0 0>;
				rates-cck = <126 126 126 126>;
				rates-ofdm = <0 0 0 0 24 24 24 24>;
				rates-mcs =
				<1 21 21 21 21 21 21 21 21 21 26>,
				<1 26 26 26 24 24 28 28 28 28 28>,
				<2 126 126 126 126 126 126 126 126 126 126>;
				rates-ru =
				<1 24 24 24 24 26 26 26 26 26 26 26 26>,
				<1 28 28 28 28 28 28 28 28 28 28 0 0>,
				<1 0 0 0 0 0 9 9 9 9 9 9 9>,
				<1 21 21 21 21 21 21 21 21 21 26 26 26>,
				<1 26 26 26 24 24 28 28 28 28 28 28 28>,
				<2 126 126 126 126 126 126 126 126 126 126 126 126>;
				rates-eht-ru =
				<1 24 24 24 24 26 26 26 26 26 26 26 26 26 0 0 0>,
				<1 28 28 28 28 28 28 28 28 28 28 0 0 0 0 0 0>,
				<1 0 0 0 0 0 9 9 9 9 9 9 9 9 9 9 9>,
				<1 21 21 21 21 21 21 21 21 21 26 26 26 26 26 26 26>,
				<1 26 26 26 24 24 28 28 28 28 28 28 28 28 28 28 24>,
				<3 126 126 126 126 126 126 126 126 126 126 126 126 126 126 126 126>,
				<1 0 0 0 0 0 0 0 0 0 0 0 0 0 0 0 0>,
				<1 9 15 15 15 15 15 15 15 15 15 15 15 15 21 21 21>,
				<1 28 28 28 28 28 28 28 28 28 28 24 24 0 0 0 0>,
				<5 126 126 126 126 126 126 126 126 126 126 126 126 126 126 126 126>;
			};
			r20 {
				channels = <140 140>;
				txs-delta = <0 0 0>;
				rates-cck = <126 126 126 126>;
				rates-ofdm = <0 0 0 0 24 24 24 24>;
				rates-mcs =
				<1 21 21 21 21 21 21 21 21 21 26>,
				<1 26 26 26 24 24 28 28 28 28 28>,
				<2 126 126 126 126 126 126 126 126 126 126>;
				rates-ru =
				<1 24 24 24 24 26 26 26 26 26 26 26 26>,
				<1 0 0 0 0 0 0 0 0 0 0 0 0>,
				<1 0 0 0 0 0 9 9 9 9 9 9 9>,
				<1 21 21 21 21 21 21 21 21 21 26 26 26>,
				<1 26 26 26 24 24 28 28 28 28 28 28 28>,
				<2 126 126 126 126 126 126 126 126 126 126 126 126>;
				rates-eht-ru =
				<1 24 24 24 24 26 26 26 26 26 26 26 26 26 0 0 0>,
				<1 0 0 0 0 0 0 0 0 0 0 0 0 0 0 0 0>,
				<1 0 0 0 0 0 9 9 9 9 9 9 9 9 9 9 9>,
				<1 21 21 21 21 21 21 21 21 21 26 26 26 26 26 26 26>,
				<1 26 26 26 24 24 28 28 28 28 28 28 28 28 28 28 24>,
				<3 126 126 126 126 126 126 126 126 126 126 126 126 126 126 126 126>,
				<1 0 0 0 0 0 0 0 0 0 0 0 0 0 0 0 0>,
				<1 9 15 15 15 15 15 15 15 15 15 15 15 15 21 21 21>,
				<1 28 28 28 28 28 28 28 28 28 28 24 24 0 0 0 0>,
				<5 126 126 126 126 126 126 126 126 126 126 126 126 126 126 126 126>;
			};
			r21 {
				channels = <144 144>;
				txs-delta = <0 0 0>;
				rates-cck = <126 126 126 126>;
				rates-ofdm = <0 0 0 0 0 0 0 0>;
				rates-mcs =
				<2 0 0 0 0 0 0 0 0 0 0>,
				<2 126 126 126 126 126 126 126 126 126 126>;
				rates-ru =
				<5 0 0 0 0 0 0 0 0 0 0 0 0>,
				<2 126 126 126 126 126 126 126 126 126 126 126 126>;
				rates-eht-ru =
				<5 0 0 0 0 0 0 0 0 0 0 0 0 0 0 0 0>,
				<3 126 126 126 126 126 126 126 126 126 126 126 126 126 126 126 126>,
				<3 0 0 0 0 0 0 0 0 0 0 0 0 0 0 0 0>,
				<5 126 126 126 126 126 126 126 126 126 126 126 126 126 126 126 126>;
			};
			r22 {
				channels = <149 161>;
				txs-delta = <0 0 0>;
				rates-cck = <126 126 126 126>;
				rates-ofdm = <0 0 0 0 10 10 10 10>;
				rates-mcs =
				<2 10 10 10 10 10 10 10 10 10 10>,
				<2 126 126 126 126 126 126 126 126 126 126>;
				rates-ru =
				<1 10 10 10 10 10 10 10 10 10 10 10 10>,
				<1 10 10 10 10 10 10 10 10 10 10 0 0>,
				<1 0 0 0 0 0 10 10 10 10 10 10 10>,
				<2 10 10 10 10 10 10 10 10 10 10 10 10>,
				<2 126 126 126 126 126 126 126 126 126 126 126 126>;
				rates-eht-ru =
				<1 10 10 10 10 10 10 10 10 10 10 10 10 10 0 0 0>,
				<1 10 10 10 10 10 10 10 10 10 10 0 0 0 10 10 10>,
				<1 0 0 0 0 0 10 10 10 10 10 10 10 10 10 10 10>,
				<2 10 10 10 10 10 10 10 10 10 10 10 10 10 10 10 10>,
				<3 126 126 126 126 126 126 126 126 126 126 126 126 126 126 126 126>,
				<1 10 10 10 10 10 10 10 0 0 0 0 0 0 0 0 0>,
				<1 10 10 10 10 10 10 10 10 10 10 10 10 10 10 10 10>,
				<1 10 10 10 10 10 10 10 10 10 10 10 10 0 0 0 0>,
				<5 126 126 126 126 126 126 126 126 126 126 126 126 126 126 126 126>;
			};
			r23 {
				channels = <165 165>;
				txs-delta = <0 0 0>;
				rates-cck = <126 126 126 126>;
				rates-ofdm = <0 0 0 0 10 10 10 10>;
				rates-mcs =
				<1 10 10 10 10 10 10 10 10 10 10>,
				<1 10 10 10 10 10 0 0 0 0 0>,
				<2 126 126 126 126 126 126 126 126 126 126>;
				rates-ru =
				<1 10 10 10 10 10 10 10 10 10 10 10 10>,
				<1 0 0 0 0 0 0 0 0 0 0 0 0>,
				<1 0 0 0 0 0 10 10 10 10 10 10 10>,
				<1 10 10 10 10 10 10 10 10 10 10 10 10>,
				<1 10 10 10 10 10 0 0 0 0 0 0 0>,
				<2 126 126 126 126 126 126 126 126 126 126 126 126>;
				rates-eht-ru =
				<1 10 10 10 10 10 10 10 10 10 10 10 10 10 0 0 0>,
				<1 0 0 0 0 0 0 0 0 0 0 0 0 0 0 0 0>,
				<1 0 0 0 0 0 10 10 10 10 10 10 10 10 10 10 10>,
				<1 10 10 10 10 10 10 10 10 10 10 10 10 10 10 10 10>,
				<1 10 10 10 10 10 0 0 0 0 0 0 0 0 0 0 0>,
				<3 126 126 126 126 126 126 126 126 126 126 126 126 126 126 126 126>,
				<1 0 0 0 0 0 0 0 0 0 0 0 0 0 0 0 0>,
				<1 10 10 10 10 10 10 10 10 10 10 10 10 10 10 10 10>,
				<1 0 0 0 0 0 0 0 0 0 0 0 0 0 0 0 0>,
				<5 126 126 126 126 126 126 126 126 126 126 126 126 126 126 126 126>;
			};
			r24 {
				channels = <169 169>;
				txs-delta = <0 0 0>;
				rates-cck = <126 126 126 126>;
				rates-ofdm = <0 0 0 0 0 0 0 0>;
				rates-mcs =
				<2 0 0 0 0 0 0 0 0 0 0>,
				<2 126 126 126 126 126 126 126 126 126 126>;
				rates-ru =
				<5 0 0 0 0 0 0 0 0 0 0 0 0>,
				<2 126 126 126 126 126 126 126 126 126 126 126 126>;
				rates-eht-ru =
				<5 0 0 0 0 0 0 0 0 0 0 0 0 0 0 0 0>,
				<3 126 126 126 126 126 126 126 126 126 126 126 126 126 126 126 126>,
				<3 0 0 0 0 0 0 0 0 0 0 0 0 0 0 0 0>,
				<5 126 126 126 126 126 126 126 126 126 126 126 126 126 126 126 126>;
			};
			r25 {
				channels = <173 173>;
				txs-delta = <0 0 0>;
				rates-cck = <126 126 126 126>;
				rates-ofdm = <0 0 0 0 0 0 0 0>;
				rates-mcs =
				<2 0 0 0 0 0 0 0 0 0 0>,
				<2 126 126 126 126 126 126 126 126 126 126>;
				rates-ru =
				<5 0 0 0 0 0 0 0 0 0 0 0 0>,
				<2 126 126 126 126 126 126 126 126 126 126 126 126>;
				rates-eht-ru =
				<5 0 0 0 0 0 0 0 0 0 0 0 0 0 0 0 0>,
				<3 126 126 126 126 126 126 126 126 126 126 126 126 126 126 126 126>,
				<3 0 0 0 0 0 0 0 0 0 0 0 0 0 0 0 0>,
				<5 126 126 126 126 126 126 126 126 126 126 126 126 126 126 126 126>;
			};
			r26 {
				channels = <177 177>;
				txs-delta = <0 0 0>;
				rates-cck = <126 126 126 126>;
				rates-ofdm = <0 0 0 0 0 0 0 0>;
				rates-mcs =
				<2 0 0 0 0 0 0 0 0 0 0>,
				<2 126 126 126 126 126 126 126 126 126 126>;
				rates-ru =
				<5 0 0 0 0 0 0 0 0 0 0 0 0>,
				<2 126 126 126 126 126 126 126 126 126 126 126 126>;
				rates-eht-ru =
				<5 0 0 0 0 0 0 0 0 0 0 0 0 0 0 0 0>,
				<3 126 126 126 126 126 126 126 126 126 126 126 126 126 126 126 126>,
				<3 0 0 0 0 0 0 0 0 0 0 0 0 0 0 0 0>,
				<5 126 126 126 126 126 126 126 126 126 126 126 126 126 126 126 126>;
			};
			r27 {
				channels = <181 181>;
				txs-delta = <0 0 0>;
				rates-cck = <126 126 126 126>;
				rates-ofdm = <0 0 0 0 0 0 0 0>;
				rates-mcs =
				<2 0 0 0 0 0 0 0 0 0 0>,
				<2 126 126 126 126 126 126 126 126 126 126>;
				rates-ru =
				<5 0 0 0 0 0 0 0 0 0 0 0 0>,
				<2 126 126 126 126 126 126 126 126 126 126 126 126>;
				rates-eht-ru =
				<5 0 0 0 0 0 0 0 0 0 0 0 0 0 0 0 0>,
				<3 126 126 126 126 126 126 126 126 126 126 126 126 126 126 126 126>,
				<3 0 0 0 0 0 0 0 0 0 0 0 0 0 0 0 0>,
				<5 126 126 126 126 126 126 126 126 126 126 126 126 126 126 126 126>;
			};
		};
	};
	ca {
		country = "CA";
		txpower-2g {
			r0 {
				channels = <1 2>;
				txs-delta = <0 0 0>;
				rates-cck = <31 31 31 31>;
				rates-ofdm = <27 27 27 27 27 27 27 27>;
				rates-mcs =
				<1 20 20 20 20 20 20 20 20 20 20>,
				<1 20 0 0 0 0 0 0 0 0 0>,
				<2 126 126 126 126 126 126 126 126 126 126>;
				rates-ru =
				<1 26 26 26 26 26 26 26 26 26 0 0 0>,
				<1 0 0 0 0 0 0 0 0 0 0 0 0>,
				<1 0 18 18 18 18 18 18 18 18 18 18 18>,
				<1 20 20 20 20 20 20 20 20 20 20 20 20>,
				<1 20 0 0 0 0 0 0 0 0 0 0 0>,
				<2 126 126 126 126 126 126 126 126 126 126 126 126>;
				rates-eht-ru =
				<1 26 26 26 26 26 26 26 26 26 0 0 0 0 0 0 0>,
				<1 0 0 0 0 0 0 0 0 0 0 0 0 0 0 0 0>,
				<1 0 18 18 18 18 18 18 18 18 18 18 18 18 20 20 20>,
				<1 20 20 20 20 20 20 20 20 20 20 20 20 20 20 20 20>,
				<1 20 0 0 0 0 0 0 0 0 0 0 0 0 0 0 0>,
				<3 126 126 126 126 126 126 126 126 126 126 126 126 126 126 126 126>,
				<1 0 0 0 0 0 0 0 0 0 0 0 0 0 0 0 0>,
				<1 20 20 20 20 20 20 20 20 20 20 20 20 20 20 20 20>,
				<1 0 0 0 0 0 0 0 0 0 0 0 0 0 0 0 0>,
				<5 126 126 126 126 126 126 126 126 126 126 126 126 126 126 126 126>;
			};
			r1 {
				channels = <3 3>;
				txs-delta = <0 0 0>;
				rates-cck = <32 32 32 32>;
				rates-ofdm = <28 28 28 28 28 28 28 28>;
				rates-mcs =
				<1 20 20 20 20 20 20 20 20 20 20>,
				<1 20 21 21 21 21 21 21 21 21 21>,
				<2 126 126 126 126 126 126 126 126 126 126>;
				rates-ru =
				<1 28 28 28 28 28 28 28 28 28 0 0 0>,
				<1 21 21 21 21 21 21 0 0 0 0 0 0>,
				<1 0 20 20 20 20 20 20 20 20 20 20 20>,
				<1 20 20 20 20 20 20 20 20 20 20 20 20>,
				<1 20 21 21 21 21 21 21 21 21 21 21 21>,
				<2 126 126 126 126 126 126 126 126 126 126 126 126>;
				rates-eht-ru =
				<1 28 28 28 28 28 28 28 28 28 0 0 0 21 21 21 21>,
				<1 21 21 21 21 21 21 0 0 0 0 0 0 0 0 0 0>,
				<1 0 20 20 20 20 20 20 20 20 20 20 20 20 20 20 20>,
				<1 20 20 20 20 20 20 20 20 20 20 20 20 20 20 20 20>,
				<1 20 21 21 21 21 21 21 21 21 21 21 21 21 0 0 0>,
				<3 126 126 126 126 126 126 126 126 126 126 126 126 126 126 126 126>,
				<1 0 0 0 0 0 0 0 0 0 0 0 0 0 0 0 0>,
				<1 20 20 20 20 20 20 20 20 20 20 20 20 20 20 20 20>,
				<1 0 0 0 0 0 0 0 0 0 0 0 0 0 0 0 0>,
				<5 126 126 126 126 126 126 126 126 126 126 126 126 126 126 126 126>;
			};
			r2 {
				channels = <4 4>;
				txs-delta = <0 0 0>;
				rates-cck = <34 34 34 34>;
				rates-ofdm = <30 30 30 30 30 30 30 30>;
				rates-mcs =
				<1 22 22 22 22 22 22 22 22 22 22>,
				<1 22 21 21 21 21 21 21 21 21 21>,
				<2 126 126 126 126 126 126 126 126 126 126>;
				rates-ru =
				<1 30 30 30 30 30 30 30 30 30 0 0 0>,
				<1 21 21 21 21 21 21 0 0 0 0 0 0>,
				<1 0 22 22 22 22 22 22 22 22 22 22 22>,
				<1 22 22 22 22 22 22 22 22 22 22 22 22>,
				<1 22 21 21 21 21 21 21 21 21 21 21 21>,
				<2 126 126 126 126 126 126 126 126 126 126 126 126>;
				rates-eht-ru =
				<1 30 30 30 30 30 30 30 30 30 0 0 0 21 21 21 21>,
				<1 21 21 21 21 21 21 0 0 0 0 0 0 0 0 0 0>,
				<1 0 22 22 22 22 22 22 22 22 22 22 22 22 22 22 22>,
				<1 22 22 22 22 22 22 22 22 22 22 22 22 22 22 22 22>,
				<1 22 21 21 21 21 21 21 21 21 21 21 21 21 0 0 0>,
				<3 126 126 126 126 126 126 126 126 126 126 126 126 126 126 126 126>,
				<1 0 0 0 0 0 0 0 0 0 0 0 0 0 0 0 0>,
				<1 22 22 22 22 22 22 22 22 22 22 22 22 22 22 22 22>,
				<1 0 0 0 0 0 0 0 0 0 0 0 0 0 0 0 0>,
				<5 126 126 126 126 126 126 126 126 126 126 126 126 126 126 126 126>;
			};
			r3 {
				channels = <5 5>;
				txs-delta = <0 0 0>;
				rates-cck = <34 34 34 34>;
				rates-ofdm = <30 30 30 30 30 30 30 30>;
				rates-mcs =
				<1 26 26 26 26 26 24 24 24 24 24>,
				<1 24 21 21 21 21 21 21 21 21 21>,
				<2 126 126 126 126 126 126 126 126 126 126>;
				rates-ru =
				<1 30 30 30 30 30 30 30 30 30 0 0 0>,
				<1 21 21 21 21 21 21 0 0 0 0 0 0>,
				<1 0 26 26 26 26 26 26 26 26 26 26 26>,
				<1 26 26 26 26 26 24 24 24 24 24 24 24>,
				<1 24 21 21 21 21 21 21 21 21 21 21 21>,
				<2 126 126 126 126 126 126 126 126 126 126 126 126>;
				rates-eht-ru =
				<1 30 30 30 30 30 30 30 30 30 0 0 0 21 21 21 21>,
				<1 21 21 21 21 21 21 0 0 0 0 0 0 0 0 0 0>,
				<1 0 26 26 26 26 26 26 26 26 26 26 26 26 26 26 26>,
				<1 26 26 26 26 26 24 24 24 24 24 24 24 24 24 24 24>,
				<1 24 21 21 21 21 21 21 21 21 21 21 21 21 0 0 0>,
				<3 126 126 126 126 126 126 126 126 126 126 126 126 126 126 126 126>,
				<1 0 0 0 0 0 0 0 0 0 0 0 0 0 0 0 0>,
				<1 26 26 26 26 26 26 26 26 26 26 26 26 26 26 26 26>,
				<1 0 0 0 0 0 0 0 0 0 0 0 0 0 0 0 0>,
				<5 126 126 126 126 126 126 126 126 126 126 126 126 126 126 126 126>;
			};
			r4 {
				channels = <6 8>;
				txs-delta = <0 0 0>;
				rates-cck = <34 34 34 34>;
				rates-ofdm = <30 30 30 30 30 30 30 30>;
				rates-mcs =
				<1 26 26 26 26 26 26 26 26 26 26>,
				<1 26 21 21 21 21 21 21 21 21 21>,
				<2 126 126 126 126 126 126 126 126 126 126>;
				rates-ru =
				<1 30 30 30 30 30 30 30 30 30 0 0 0>,
				<1 21 21 21 21 21 21 0 0 0 0 0 0>,
				<1 0 28 28 28 28 28 28 28 28 28 28 28>,
				<1 26 26 26 26 26 26 26 26 26 26 26 26>,
				<1 26 21 21 21 21 21 21 21 21 21 21 21>,
				<2 126 126 126 126 126 126 126 126 126 126 126 126>;
				rates-eht-ru =
				<1 30 30 30 30 30 30 30 30 30 0 0 0 21 21 21 21>,
				<1 21 21 21 21 21 21 0 0 0 0 0 0 0 0 0 0>,
				<1 0 28 28 28 28 28 28 28 28 28 28 28 28 26 26 26>,
				<1 26 26 26 26 26 26 26 26 26 26 26 26 26 26 26 26>,
				<1 26 21 21 21 21 21 21 21 21 21 21 21 21 0 0 0>,
				<3 126 126 126 126 126 126 126 126 126 126 126 126 126 126 126 126>,
				<1 0 0 0 0 0 0 0 0 0 0 0 0 0 0 0 0>,
				<1 26 26 26 26 26 26 26 26 26 26 26 26 26 26 26 26>,
				<1 0 0 0 0 0 0 0 0 0 0 0 0 0 0 0 0>,
				<5 126 126 126 126 126 126 126 126 126 126 126 126 126 126 126 126>;
			};
			r5 {
				channels = <9 9>;
				txs-delta = <0 0 0>;
				rates-cck = <34 34 34 34>;
				rates-ofdm = <28 28 28 28 28 28 28 28>;
				rates-mcs =
				<1 23 23 23 23 23 24 24 24 24 24>,
				<1 24 21 21 21 21 21 21 21 21 21>,
				<2 126 126 126 126 126 126 126 126 126 126>;
				rates-ru =
				<1 27 27 27 27 27 27 27 27 27 0 0 0>,
				<1 21 21 21 21 21 21 0 0 0 0 0 0>,
				<1 0 26 26 26 26 26 26 26 26 26 26 26>,
				<1 23 23 23 23 23 24 24 24 24 24 24 24>,
				<1 24 21 21 21 21 21 21 21 21 21 21 21>,
				<2 126 126 126 126 126 126 126 126 126 126 126 126>;
				rates-eht-ru =
				<1 27 27 27 27 27 27 27 27 27 0 0 0 21 21 21 21>,
				<1 21 21 21 21 21 21 0 0 0 0 0 0 0 0 0 0>,
				<1 0 26 26 26 26 26 26 26 26 26 26 26 26 26 26 26>,
				<1 23 23 23 23 23 24 24 24 24 24 24 24 24 24 24 24>,
				<1 24 21 21 21 21 21 21 21 21 21 21 21 21 0 0 0>,
				<3 126 126 126 126 126 126 126 126 126 126 126 126 126 126 126 126>,
				<1 0 0 0 0 0 0 0 0 0 0 0 0 0 0 0 0>,
				<1 26 26 26 26 26 26 26 26 26 23 23 23 23 23 23 23>,
				<1 0 0 0 0 0 0 0 0 0 0 0 0 0 0 0 0>,
				<5 126 126 126 126 126 126 126 126 126 126 126 126 126 126 126 126>;
			};
			r6 {
				channels = <10 11>;
				txs-delta = <0 0 0>;
				rates-cck = <34 34 34 34>;
				rates-ofdm = <27 27 27 27 27 27 27 27>;
				rates-mcs =
				<1 21 21 21 21 21 24 24 24 24 24>,
				<1 24 0 0 0 0 0 0 0 0 0>,
				<2 126 126 126 126 126 126 126 126 126 126>;
				rates-ru =
				<1 25 25 25 25 25 25 25 25 25 0 0 0>,
				<1 0 0 0 0 0 0 0 0 0 0 0 0>,
				<1 0 22 22 22 22 22 22 22 22 22 22 22>,
				<1 21 21 21 21 21 24 24 24 24 24 24 24>,
				<1 24 0 0 0 0 0 0 0 0 0 0 0>,
				<2 126 126 126 126 126 126 126 126 126 126 126 126>;
				rates-eht-ru =
				<1 25 25 25 25 25 25 25 25 25 0 0 0 0 0 0 0>,
				<1 0 0 0 0 0 0 0 0 0 0 0 0 0 0 0 0>,
				<1 0 22 22 22 22 22 22 22 22 22 22 22 22 25 25 25>,
				<1 21 21 21 21 21 24 24 24 24 24 24 24 24 24 24 24>,
				<1 24 0 0 0 0 0 0 0 0 0 0 0 0 0 0 0>,
				<3 126 126 126 126 126 126 126 126 126 126 126 126 126 126 126 126>,
				<1 0 0 0 0 0 0 0 0 0 0 0 0 0 0 0 0>,
				<1 25 25 25 25 25 25 25 25 25 21 21 21 21 21 21 21>,
				<1 0 0 0 0 0 0 0 0 0 0 0 0 0 0 0 0>,
				<5 126 126 126 126 126 126 126 126 126 126 126 126 126 126 126 126>;
			};
			r7 {
				channels = <12 14>;
				txs-delta = <0 0 0>;
				rates-cck = <0 0 0 0>;
				rates-ofdm = <0 0 0 0 0 0 0 0>;
				rates-mcs =
				<2 0 0 0 0 0 0 0 0 0 0>,
				<2 126 126 126 126 126 126 126 126 126 126>;
				rates-ru =
				<5 0 0 0 0 0 0 0 0 0 0 0 0>,
				<2 126 126 126 126 126 126 126 126 126 126 126 126>;
				rates-eht-ru =
				<5 0 0 0 0 0 0 0 0 0 0 0 0 0 0 0 0>,
				<3 126 126 126 126 126 126 126 126 126 126 126 126 126 126 126 126>,
				<3 0 0 0 0 0 0 0 0 0 0 0 0 0 0 0 0>,
				<5 126 126 126 126 126 126 126 126 126 126 126 126 126 126 126 126>;
			};
		};
		txpower-5g {
			r0 {
				channels = <184 196>;
				txs-delta = <0 0 0>;
				rates-cck = <126 126 126 126>;
				rates-ofdm = <0 0 0 0 0 0 0 0>;
				rates-mcs =
				<2 0 0 0 0 0 0 0 0 0 0>,
				<2 126 126 126 126 126 126 126 126 126 126>;
				rates-ru =
				<5 0 0 0 0 0 0 0 0 0 0 0 0>,
				<2 126 126 126 126 126 126 126 126 126 126 126 126>;
				rates-eht-ru =
				<5 0 0 0 0 0 0 0 0 0 0 0 0 0 0 0 0>,
				<3 126 126 126 126 126 126 126 126 126 126 126 126 126 126 126 126>,
				<3 0 0 0 0 0 0 0 0 0 0 0 0 0 0 0 0>,
				<5 126 126 126 126 126 126 126 126 126 126 126 126 126 126 126 126>;
			};
			r1 {
				channels = <8 16>;
				txs-delta = <0 0 0>;
				rates-cck = <126 126 126 126>;
				rates-ofdm = <0 0 0 0 0 0 0 0>;
				rates-mcs =
				<2 0 0 0 0 0 0 0 0 0 0>,
				<2 126 126 126 126 126 126 126 126 126 126>;
				rates-ru =
				<5 0 0 0 0 0 0 0 0 0 0 0 0>,
				<2 126 126 126 126 126 126 126 126 126 126 126 126>;
				rates-eht-ru =
				<5 0 0 0 0 0 0 0 0 0 0 0 0 0 0 0 0>,
				<3 126 126 126 126 126 126 126 126 126 126 126 126 126 126 126 126>,
				<3 0 0 0 0 0 0 0 0 0 0 0 0 0 0 0 0>,
				<5 126 126 126 126 126 126 126 126 126 126 126 126 126 126 126 126>;
			};
			r2 {
				channels = <36 40>;
				txs-delta = <0 0 0>;
				rates-cck = <126 126 126 126>;
				rates-ofdm = <0 0 0 0 19 19 19 19>;
				rates-mcs =
				<1 16 16 16 16 16 16 16 16 16 21>,
				<1 21 21 21 21 21 22 22 22 22 22>,
				<2 126 126 126 126 126 126 126 126 126 126>;
				rates-ru =
				<1 19 19 19 19 21 21 21 21 21 21 21 21>,
				<1 22 22 22 22 22 22 22 22 22 22 0 0>,
				<1 0 0 0 0 0 4 4 4 4 4 4 4>,
				<1 16 16 16 16 16 16 16 16 16 21 21 21>,
				<1 21 21 21 21 21 22 22 22 22 22 22 22>,
				<2 126 126 126 126 126 126 126 126 126 126 126 126>;
				rates-eht-ru =
				<1 19 19 19 19 21 21 21 21 21 21 21 21 21 0 0 0>,
				<1 22 22 22 22 22 22 22 22 22 22 0 0 0 16 16 16>,
				<1 0 0 0 0 0 4 4 4 4 4 4 4 4 4 4 4>,
				<1 16 16 16 16 16 16 16 16 16 21 21 21 21 21 21 21>,
				<1 21 21 21 21 21 22 22 22 22 22 22 22 22 22 22 22>,
				<3 126 126 126 126 126 126 126 126 126 126 126 126 126 126 126 126>,
				<1 16 16 16 16 16 16 16 0 0 0 0 0 0 0 0 0>,
				<1 4 10 10 10 10 10 10 10 10 10 10 10 10 16 16 16>,
				<1 16 16 16 16 16 16 16 16 16 16 16 16 0 0 0 0>,
				<5 126 126 126 126 126 126 126 126 126 126 126 126 126 126 126 126>;
			};
			r3 {
				channels = <44 48>;
				txs-delta = <0 0 0>;
				rates-cck = <126 126 126 126>;
				rates-ofdm = <0 0 0 0 19 19 19 19>;
				rates-mcs =
				<1 16 16 16 16 16 16 16 16 16 21>,
				<1 21 21 21 21 21 22 22 22 22 22>,
				<2 126 126 126 126 126 126 126 126 126 126>;
				rates-ru =
				<1 19 19 19 19 21 21 21 21 21 21 21 21>,
				<1 27 27 27 27 27 27 27 27 27 27 0 0>,
				<1 0 0 0 0 0 4 4 4 4 4 4 4>,
				<1 16 16 16 16 16 16 16 16 16 21 21 21>,
				<1 21 21 21 21 21 22 22 22 22 22 22 22>,
				<2 126 126 126 126 126 126 126 126 126 126 126 126>;
				rates-eht-ru =
				<1 19 19 19 19 21 21 21 21 21 21 21 21 21 0 0 0>,
				<1 27 27 27 27 27 27 27 27 27 27 0 0 0 16 16 16>,
				<1 0 0 0 0 0 4 4 4 4 4 4 4 4 4 4 4>,
				<1 16 16 16 16 16 16 16 16 16 21 21 21 21 21 21 21>,
				<1 21 21 21 21 21 22 22 22 22 22 22 22 22 22 22 22>,
				<3 126 126 126 126 126 126 126 126 126 126 126 126 126 126 126 126>,
				<1 16 16 16 16 16 16 16 0 0 0 0 0 0 0 0 0>,
				<1 4 10 10 10 10 10 10 10 10 10 10 10 10 16 16 16>,
				<1 16 16 16 16 16 16 16 16 16 16 16 16 0 0 0 0>,
				<5 126 126 126 126 126 126 126 126 126 126 126 126 126 126 126 126>;
			};
			r4 {
				channels = <52 52>;
				txs-delta = <0 0 0>;
				rates-cck = <126 126 126 126>;
				rates-ofdm = <0 0 0 0 29 29 29 29>;
				rates-mcs =
				<1 22 22 22 22 22 22 22 22 22 24>,
				<1 24 24 24 24 24 22 22 22 22 22>,
				<2 126 126 126 126 126 126 126 126 126 126>;
				rates-ru =
				<1 29 29 29 29 29 29 29 29 29 29 29 29>,
				<1 27 27 27 27 27 27 27 27 27 27 0 0>,
				<1 0 0 0 0 0 18 18 18 18 18 18 18>,
				<1 22 22 22 22 22 22 22 22 22 24 24 24>,
				<1 24 24 24 24 24 22 22 22 22 22 22 22>,
				<2 126 126 126 126 126 126 126 126 126 126 126 126>;
				rates-eht-ru =
				<1 29 29 29 29 29 29 29 29 29 29 29 29 29 0 0 0>,
				<1 27 27 27 27 27 27 27 27 27 27 0 0 0 18 18 18>,
				<1 0 0 0 0 0 18 18 18 18 18 18 18 18 18 18 18>,
				<1 22 22 22 22 22 22 22 22 22 24 24 24 24 24 24 24>,
				<1 24 24 24 24 24 22 22 22 22 22 22 22 22 22 22 22>,
				<3 126 126 126 126 126 126 126 126 126 126 126 126 126 126 126 126>,
				<1 18 18 18 18 18 18 18 0 0 0 0 0 0 0 0 0>,
				<1 18 20 20 20 20 20 20 20 20 20 20 20 20 22 22 22>,
				<1 18 18 18 18 18 18 18 18 18 18 18 18 0 0 0 0>,
				<5 126 126 126 126 126 126 126 126 126 126 126 126 126 126 126 126>;
			};
			r5 {
				channels = <56 56>;
				txs-delta = <0 0 0>;
				rates-cck = <126 126 126 126>;
				rates-ofdm = <0 0 0 0 28 28 28 28>;
				rates-mcs =
				<1 22 22 22 22 22 22 22 22 22 24>,
				<1 24 24 24 24 24 22 22 22 22 22>,
				<2 126 126 126 126 126 126 126 126 126 126>;
				rates-ru =
				<1 28 28 28 28 28 28 28 28 28 28 28 28>,
				<1 27 27 27 27 27 27 27 27 27 27 0 0>,
				<1 0 0 0 0 0 18 18 18 18 18 18 18>,
				<1 22 22 22 22 22 22 22 22 22 24 24 24>,
				<1 24 24 24 24 24 22 22 22 22 22 22 22>,
				<2 126 126 126 126 126 126 126 126 126 126 126 126>;
				rates-eht-ru =
				<1 28 28 28 28 28 28 28 28 28 28 28 28 28 0 0 0>,
				<1 27 27 27 27 27 27 27 27 27 27 0 0 0 18 18 18>,
				<1 0 0 0 0 0 18 18 18 18 18 18 18 18 18 18 18>,
				<1 22 22 22 22 22 22 22 22 22 24 24 24 24 24 24 24>,
				<1 24 24 24 24 24 22 22 22 22 22 22 22 22 22 22 22>,
				<3 126 126 126 126 126 126 126 126 126 126 126 126 126 126 126 126>,
				<1 18 18 18 18 18 18 18 0 0 0 0 0 0 0 0 0>,
				<1 18 20 20 20 20 20 20 20 20 20 20 20 20 22 22 22>,
				<1 18 18 18 18 18 18 18 18 18 18 18 18 0 0 0 0>,
				<5 126 126 126 126 126 126 126 126 126 126 126 126 126 126 126 126>;
			};
			r6 {
				channels = <60 60>;
				txs-delta = <0 0 0>;
				rates-cck = <126 126 126 126>;
				rates-ofdm = <0 0 0 0 27 27 27 27>;
				rates-mcs =
				<1 22 22 22 22 22 22 22 22 22 23>,
				<1 23 23 23 23 23 22 22 22 22 22>,
				<2 126 126 126 126 126 126 126 126 126 126>;
				rates-ru =
				<1 27 27 27 27 27 27 27 27 27 27 27 27>,
				<1 22 22 22 22 22 22 22 22 22 22 0 0>,
				<1 0 0 0 0 0 18 18 18 18 18 18 18>,
				<1 22 22 22 22 22 22 22 22 22 23 23 23>,
				<1 23 23 23 23 23 22 22 22 22 22 22 22>,
				<2 126 126 126 126 126 126 126 126 126 126 126 126>;
				rates-eht-ru =
				<1 27 27 27 27 27 27 27 27 27 27 27 27 27 0 0 0>,
				<1 22 22 22 22 22 22 22 22 22 22 0 0 0 18 18 18>,
				<1 0 0 0 0 0 18 18 18 18 18 18 18 18 18 18 18>,
				<1 22 22 22 22 22 22 22 22 22 23 23 23 23 23 23 23>,
				<1 23 23 23 23 23 22 22 22 22 22 22 22 22 22 22 22>,
				<3 126 126 126 126 126 126 126 126 126 126 126 126 126 126 126 126>,
				<1 18 18 18 18 18 18 18 0 0 0 0 0 0 0 0 0>,
				<1 18 20 20 20 20 20 20 20 20 20 20 20 20 22 22 22>,
				<1 18 18 18 18 18 18 18 18 18 18 18 18 0 0 0 0>,
				<5 126 126 126 126 126 126 126 126 126 126 126 126 126 126 126 126>;
			};
			r7 {
				channels = <64 64>;
				txs-delta = <0 0 0>;
				rates-cck = <126 126 126 126>;
				rates-ofdm = <0 0 0 0 24 24 24 24>;
				rates-mcs =
				<1 20 20 20 20 20 20 20 20 20 23>,
				<1 23 23 23 23 23 22 22 22 22 22>,
				<2 126 126 126 126 126 126 126 126 126 126>;
				rates-ru =
				<1 24 24 24 24 24 24 24 24 24 24 24 24>,
				<1 22 22 22 22 22 22 22 22 22 22 0 0>,
				<1 0 0 0 0 0 18 18 18 18 18 18 18>,
				<1 20 20 20 20 20 20 20 20 20 23 23 23>,
				<1 23 23 23 23 23 22 22 22 22 22 22 22>,
				<2 126 126 126 126 126 126 126 126 126 126 126 126>;
				rates-eht-ru =
				<1 24 24 24 24 24 24 24 24 24 24 24 24 24 0 0 0>,
				<1 22 22 22 22 22 22 22 22 22 22 0 0 0 18 18 18>,
				<1 0 0 0 0 0 18 18 18 18 18 18 18 18 18 18 18>,
				<1 20 20 20 20 20 20 20 20 20 23 23 23 23 23 23 23>,
				<1 23 23 23 23 23 22 22 22 22 22 22 22 22 22 22 22>,
				<3 126 126 126 126 126 126 126 126 126 126 126 126 126 126 126 126>,
				<1 18 18 18 18 18 18 18 0 0 0 0 0 0 0 0 0>,
				<1 18 20 20 20 20 20 20 20 20 20 20 20 20 20 20 20>,
				<1 18 18 18 18 18 18 18 18 18 18 18 18 0 0 0 0>,
				<5 126 126 126 126 126 126 126 126 126 126 126 126 126 126 126 126>;
			};
			r8 {
				channels = <68 68>;
				txs-delta = <0 0 0>;
				rates-cck = <126 126 126 126>;
				rates-ofdm = <0 0 0 0 0 0 0 0>;
				rates-mcs =
				<2 0 0 0 0 0 0 0 0 0 0>,
				<2 126 126 126 126 126 126 126 126 126 126>;
				rates-ru =
				<5 0 0 0 0 0 0 0 0 0 0 0 0>,
				<2 126 126 126 126 126 126 126 126 126 126 126 126>;
				rates-eht-ru =
				<5 0 0 0 0 0 0 0 0 0 0 0 0 0 0 0 0>,
				<3 126 126 126 126 126 126 126 126 126 126 126 126 126 126 126 126>,
				<3 0 0 0 0 0 0 0 0 0 0 0 0 0 0 0 0>,
				<5 126 126 126 126 126 126 126 126 126 126 126 126 126 126 126 126>;
			};
			r9 {
				channels = <72 72>;
				txs-delta = <0 0 0>;
				rates-cck = <126 126 126 126>;
				rates-ofdm = <0 0 0 0 0 0 0 0>;
				rates-mcs =
				<2 0 0 0 0 0 0 0 0 0 0>,
				<2 126 126 126 126 126 126 126 126 126 126>;
				rates-ru =
				<5 0 0 0 0 0 0 0 0 0 0 0 0>,
				<2 126 126 126 126 126 126 126 126 126 126 126 126>;
				rates-eht-ru =
				<5 0 0 0 0 0 0 0 0 0 0 0 0 0 0 0 0>,
				<3 126 126 126 126 126 126 126 126 126 126 126 126 126 126 126 126>,
				<3 0 0 0 0 0 0 0 0 0 0 0 0 0 0 0 0>,
				<5 126 126 126 126 126 126 126 126 126 126 126 126 126 126 126 126>;
			};
			r10 {
				channels = <76 76>;
				txs-delta = <0 0 0>;
				rates-cck = <126 126 126 126>;
				rates-ofdm = <0 0 0 0 0 0 0 0>;
				rates-mcs =
				<2 0 0 0 0 0 0 0 0 0 0>,
				<2 126 126 126 126 126 126 126 126 126 126>;
				rates-ru =
				<5 0 0 0 0 0 0 0 0 0 0 0 0>,
				<2 126 126 126 126 126 126 126 126 126 126 126 126>;
				rates-eht-ru =
				<5 0 0 0 0 0 0 0 0 0 0 0 0 0 0 0 0>,
				<3 126 126 126 126 126 126 126 126 126 126 126 126 126 126 126 126>,
				<3 0 0 0 0 0 0 0 0 0 0 0 0 0 0 0 0>,
				<5 126 126 126 126 126 126 126 126 126 126 126 126 126 126 126 126>;
			};
			r11 {
				channels = <80 80>;
				txs-delta = <0 0 0>;
				rates-cck = <126 126 126 126>;
				rates-ofdm = <0 0 0 0 0 0 0 0>;
				rates-mcs =
				<2 0 0 0 0 0 0 0 0 0 0>,
				<2 126 126 126 126 126 126 126 126 126 126>;
				rates-ru =
				<5 0 0 0 0 0 0 0 0 0 0 0 0>,
				<2 126 126 126 126 126 126 126 126 126 126 126 126>;
				rates-eht-ru =
				<5 0 0 0 0 0 0 0 0 0 0 0 0 0 0 0 0>,
				<3 126 126 126 126 126 126 126 126 126 126 126 126 126 126 126 126>,
				<3 0 0 0 0 0 0 0 0 0 0 0 0 0 0 0 0>,
				<5 126 126 126 126 126 126 126 126 126 126 126 126 126 126 126 126>;
			};
			r12 {
				channels = <84 84>;
				txs-delta = <0 0 0>;
				rates-cck = <126 126 126 126>;
				rates-ofdm = <0 0 0 0 0 0 0 0>;
				rates-mcs =
				<2 0 0 0 0 0 0 0 0 0 0>,
				<2 126 126 126 126 126 126 126 126 126 126>;
				rates-ru =
				<5 0 0 0 0 0 0 0 0 0 0 0 0>,
				<2 126 126 126 126 126 126 126 126 126 126 126 126>;
				rates-eht-ru =
				<5 0 0 0 0 0 0 0 0 0 0 0 0 0 0 0 0>,
				<3 126 126 126 126 126 126 126 126 126 126 126 126 126 126 126 126>,
				<3 0 0 0 0 0 0 0 0 0 0 0 0 0 0 0 0>,
				<5 126 126 126 126 126 126 126 126 126 126 126 126 126 126 126 126>;
			};
			r13 {
				channels = <88 88>;
				txs-delta = <0 0 0>;
				rates-cck = <126 126 126 126>;
				rates-ofdm = <0 0 0 0 0 0 0 0>;
				rates-mcs =
				<2 0 0 0 0 0 0 0 0 0 0>,
				<2 126 126 126 126 126 126 126 126 126 126>;
				rates-ru =
				<5 0 0 0 0 0 0 0 0 0 0 0 0>,
				<2 126 126 126 126 126 126 126 126 126 126 126 126>;
				rates-eht-ru =
				<5 0 0 0 0 0 0 0 0 0 0 0 0 0 0 0 0>,
				<3 126 126 126 126 126 126 126 126 126 126 126 126 126 126 126 126>,
				<3 0 0 0 0 0 0 0 0 0 0 0 0 0 0 0 0>,
				<5 126 126 126 126 126 126 126 126 126 126 126 126 126 126 126 126>;
			};
			r14 {
				channels = <92 92>;
				txs-delta = <0 0 0>;
				rates-cck = <126 126 126 126>;
				rates-ofdm = <0 0 0 0 0 0 0 0>;
				rates-mcs =
				<2 0 0 0 0 0 0 0 0 0 0>,
				<2 126 126 126 126 126 126 126 126 126 126>;
				rates-ru =
				<5 0 0 0 0 0 0 0 0 0 0 0 0>,
				<2 126 126 126 126 126 126 126 126 126 126 126 126>;
				rates-eht-ru =
				<5 0 0 0 0 0 0 0 0 0 0 0 0 0 0 0 0>,
				<3 126 126 126 126 126 126 126 126 126 126 126 126 126 126 126 126>,
				<3 0 0 0 0 0 0 0 0 0 0 0 0 0 0 0 0>,
				<5 126 126 126 126 126 126 126 126 126 126 126 126 126 126 126 126>;
			};
			r15 {
				channels = <96 96>;
				txs-delta = <0 0 0>;
				rates-cck = <126 126 126 126>;
				rates-ofdm = <0 0 0 0 0 0 0 0>;
				rates-mcs =
				<2 0 0 0 0 0 0 0 0 0 0>,
				<2 126 126 126 126 126 126 126 126 126 126>;
				rates-ru =
				<5 0 0 0 0 0 0 0 0 0 0 0 0>,
				<2 126 126 126 126 126 126 126 126 126 126 126 126>;
				rates-eht-ru =
				<5 0 0 0 0 0 0 0 0 0 0 0 0 0 0 0 0>,
				<3 126 126 126 126 126 126 126 126 126 126 126 126 126 126 126 126>,
				<3 0 0 0 0 0 0 0 0 0 0 0 0 0 0 0 0>,
				<5 126 126 126 126 126 126 126 126 126 126 126 126 126 126 126 126>;
			};
			r16 {
				channels = <100 100>;
				txs-delta = <0 0 0>;
				rates-cck = <126 126 126 126>;
				rates-ofdm = <0 0 0 0 24 24 24 24>;
				rates-mcs =
				<1 20 20 20 20 20 20 20 20 20 24>,
				<1 24 24 24 24 24 20 20 20 20 20>,
				<2 126 126 126 126 126 126 126 126 126 126>;
				rates-ru =
				<1 24 24 24 24 25 25 25 25 25 25 25 25>,
				<1 24 24 24 24 24 24 24 24 24 24 0 0>,
				<1 0 0 0 0 0 16 16 16 16 16 16 16>,
				<1 20 20 20 20 20 20 20 20 20 24 24 24>,
				<1 24 24 24 24 24 20 20 20 20 20 20 20>,
				<2 126 126 126 126 126 126 126 126 126 126 126 126>;
				rates-eht-ru =
				<1 24 24 24 24 25 25 25 25 25 25 25 25 25 0 0 0>,
				<1 24 24 24 24 24 24 24 24 24 24 0 0 0 22 22 22>,
				<1 0 0 0 0 0 16 16 16 16 16 16 16 16 16 16 16>,
				<1 20 20 20 20 20 20 20 20 20 24 24 24 24 24 24 24>,
				<1 24 24 24 24 24 20 20 20 20 20 20 20 20 20 20 20>,
				<3 126 126 126 126 126 126 126 126 126 126 126 126 126 126 126 126>,
				<1 22 22 22 22 22 22 22 0 0 0 0 0 0 0 0 0>,
				<1 16 18 18 18 18 18 18 18 18 18 18 18 18 20 20 20>,
				<1 22 22 22 22 22 22 22 22 22 22 22 22 0 0 0 0>,
				<5 126 126 126 126 126 126 126 126 126 126 126 126 126 126 126 126>;
			};
			r17 {
				channels = <104 104>;
				txs-delta = <0 0 0>;
				rates-cck = <126 126 126 126>;
				rates-ofdm = <0 0 0 0 28 28 28 28>;
				rates-mcs =
				<1 20 20 20 20 20 20 20 20 20 24>,
				<1 24 24 24 24 24 20 20 20 20 20>,
				<2 126 126 126 126 126 126 126 126 126 126>;
				rates-ru =
				<1 28 28 28 28 29 29 29 29 29 29 29 29>,
				<1 24 24 24 24 24 24 24 24 24 24 0 0>,
				<1 0 0 0 0 0 16 16 16 16 16 16 16>,
				<1 20 20 20 20 20 20 20 20 20 24 24 24>,
				<1 24 24 24 24 24 20 20 20 20 20 20 20>,
				<2 126 126 126 126 126 126 126 126 126 126 126 126>;
				rates-eht-ru =
				<1 28 28 28 28 29 29 29 29 29 29 29 29 29 0 0 0>,
				<1 24 24 24 24 24 24 24 24 24 24 0 0 0 22 22 22>,
				<1 0 0 0 0 0 16 16 16 16 16 16 16 16 16 16 16>,
				<1 20 20 20 20 20 20 20 20 20 24 24 24 24 24 24 24>,
				<1 24 24 24 24 24 20 20 20 20 20 20 20 20 20 20 20>,
				<3 126 126 126 126 126 126 126 126 126 126 126 126 126 126 126 126>,
				<1 22 22 22 22 22 22 22 0 0 0 0 0 0 0 0 0>,
				<1 16 18 18 18 18 18 18 18 18 18 18 18 18 20 20 20>,
				<1 22 22 22 22 22 22 22 22 22 22 22 22 0 0 0 0>,
				<5 126 126 126 126 126 126 126 126 126 126 126 126 126 126 126 126>;
			};
			r18 {
				channels = <108 108>;
				txs-delta = <0 0 0>;
				rates-cck = <126 126 126 126>;
				rates-ofdm = <0 0 0 0 32 32 32 32>;
				rates-mcs =
				<1 20 20 20 20 20 20 20 20 20 24>,
				<1 24 24 24 24 24 20 20 20 20 20>,
				<2 126 126 126 126 126 126 126 126 126 126>;
				rates-ru =
				<1 32 32 32 32 33 33 33 33 33 32 32 32>,
				<1 28 28 28 28 28 28 28 28 28 28 0 0>,
				<1 0 0 0 0 0 16 16 16 16 16 16 16>,
				<1 20 20 20 20 20 20 20 20 20 24 24 24>,
				<1 24 24 24 24 24 20 20 20 20 20 20 20>,
				<2 126 126 126 126 126 126 126 126 126 126 126 126>;
				rates-eht-ru =
				<1 32 32 32 32 33 33 33 33 33 32 32 32 32 0 0 0>,
				<1 28 28 28 28 28 28 28 28 28 28 0 0 0 22 22 22>,
				<1 0 0 0 0 0 16 16 16 16 16 16 16 16 16 16 16>,
				<1 20 20 20 20 20 20 20 20 20 24 24 24 24 24 24 24>,
				<1 24 24 24 24 24 20 20 20 20 20 20 20 20 20 20 20>,
				<3 126 126 126 126 126 126 126 126 126 126 126 126 126 126 126 126>,
				<1 22 22 22 22 22 22 22 0 0 0 0 0 0 0 0 0>,
				<1 16 20 20 20 20 20 20 20 20 20 20 20 20 20 20 20>,
				<1 22 22 22 22 22 22 22 22 22 22 22 22 0 0 0 0>,
				<5 126 126 126 126 126 126 126 126 126 126 126 126 126 126 126 126>;
			};
			r19 {
				channels = <112 112>;
				txs-delta = <0 0 0>;
				rates-cck = <126 126 126 126>;
				rates-ofdm = <0 0 0 0 33 33 33 33>;
				rates-mcs =
				<1 20 20 20 20 20 20 20 20 20 24>,
				<1 24 24 24 24 24 20 20 20 20 20>,
				<2 126 126 126 126 126 126 126 126 126 126>;
				rates-ru =
				<1 33 33 32 32 33 33 33 33 33 32 32 32>,
				<1 28 28 28 28 28 28 28 28 28 28 0 0>,
				<1 0 0 0 0 0 16 16 16 16 16 16 16>,
				<1 20 20 20 20 20 20 20 20 20 24 24 24>,
				<1 24 24 24 24 24 20 20 20 20 20 20 20>,
				<2 126 126 126 126 126 126 126 126 126 126 126 126>;
				rates-eht-ru =
				<1 33 33 32 32 33 33 33 33 33 32 32 32 32 0 0 0>,
				<1 28 28 28 28 28 28 28 28 28 28 0 0 0 22 22 22>,
				<1 0 0 0 0 0 16 16 16 16 16 16 16 16 16 16 16>,
				<1 20 20 20 20 20 20 20 20 20 24 24 24 24 24 24 24>,
				<1 24 24 24 24 24 20 20 20 20 20 20 20 20 20 20 20>,
				<3 126 126 126 126 126 126 126 126 126 126 126 126 126 126 126 126>,
				<1 22 22 22 22 22 22 22 0 0 0 0 0 0 0 0 0>,
				<1 16 20 20 20 20 20 20 20 20 20 20 20 20 20 20 20>,
				<1 22 22 22 22 22 22 22 22 22 22 22 22 0 0 0 0>,
				<5 126 126 126 126 126 126 126 126 126 126 126 126 126 126 126 126>;
			};
			r20 {
				channels = <116 116>;
				txs-delta = <0 0 0>;
				rates-cck = <126 126 126 126>;
				rates-ofdm = <0 0 0 0 33 33 33 33>;
				rates-mcs =
				<1 30 30 30 30 30 28 28 26 26 33>,
				<1 32 28 28 26 26 0 0 0 0 0>,
				<2 126 126 126 126 126 126 126 126 126 126>;
				rates-ru =
				<1 33 33 32 32 33 33 33 33 33 32 32 32>,
				<1 0 0 0 0 0 0 0 0 0 0 0 0>,
				<1 0 0 0 0 0 18 18 18 18 18 18 18>,
				<1 30 30 30 30 30 28 28 26 26 33 33 33>,
				<1 32 28 28 26 26 0 0 0 0 0 0 0>,
				<2 126 126 126 126 126 126 126 126 126 126 126 126>;
				rates-eht-ru =
				<1 33 33 32 32 33 33 33 33 33 32 32 32 32 0 0 0>,
				<1 0 0 0 0 0 0 0 0 0 0 0 0 0 0 0 0>,
				<1 0 0 0 0 0 18 18 18 18 18 18 18 18 18 18 18>,
				<1 30 30 30 30 30 28 28 26 26 33 33 33 33 33 32 32>,
				<1 32 28 28 26 26 0 0 0 0 0 0 0 0 0 0 0>,
				<3 126 126 126 126 126 126 126 126 126 126 126 126 126 126 126 126>,
				<1 0 0 0 0 0 0 0 0 0 0 0 0 0 0 0 0>,
				<1 18 24 24 24 24 24 24 24 24 24 24 24 24 30 30 30>,
				<1 0 0 0 0 0 0 0 0 0 0 0 0 0 0 0 0>,
				<5 126 126 126 126 126 126 126 126 126 126 126 126 126 126 126 126>;
			};
			r21 {
				channels = <120 120>;
				txs-delta = <0 0 0>;
				rates-cck = <126 126 126 126>;
				rates-ofdm = <0 0 0 0 33 33 33 33>;
				rates-mcs =
				<2 0 0 0 0 0 0 0 0 0 0>,
				<2 126 126 126 126 126 126 126 126 126 126>;
				rates-ru =
				<1 33 33 32 32 33 33 33 33 33 32 32 32>,
				<4 0 0 0 0 0 0 0 0 0 0 0 0>,
				<2 126 126 126 126 126 126 126 126 126 126 126 126>;
				rates-eht-ru =
				<1 33 33 32 32 33 33 33 33 33 32 32 32 32 0 0 0>,
				<4 0 0 0 0 0 0 0 0 0 0 0 0 0 0 0 0>,
				<3 126 126 126 126 126 126 126 126 126 126 126 126 126 126 126 126>,
				<3 0 0 0 0 0 0 0 0 0 0 0 0 0 0 0 0>,
				<5 126 126 126 126 126 126 126 126 126 126 126 126 126 126 126 126>;
			};
			r22 {
				channels = <124 124>;
				txs-delta = <0 0 0>;
				rates-cck = <126 126 126 126>;
				rates-ofdm = <0 0 0 0 33 33 33 33>;
				rates-mcs =
				<1 28 28 28 28 28 28 28 24 24 30>,
				<1 30 28 28 24 24 30 30 30 30 30>,
				<2 126 126 126 126 126 126 126 126 126 126>;
				rates-ru =
				<1 33 33 32 32 33 33 33 33 33 32 32 32>,
				<1 30 30 30 30 30 30 30 30 28 28 0 0>,
				<1 0 0 0 0 0 10 10 10 10 10 10 10>,
				<1 28 28 28 28 28 28 28 24 24 30 30 30>,
				<1 30 28 28 24 24 30 30 30 30 30 30 30>,
				<2 126 126 126 126 126 126 126 126 126 126 126 126>;
				rates-eht-ru =
				<1 33 33 32 32 33 33 33 33 33 32 32 32 32 0 0 0>,
				<1 30 30 30 30 30 30 30 30 28 28 0 0 0 0 0 0>,
				<1 0 0 0 0 0 10 10 10 10 10 10 10 10 10 10 10>,
				<1 28 28 28 28 28 28 28 24 24 30 30 30 30 30 30 30>,
				<1 30 28 28 24 24 30 30 30 30 30 30 30 30 28 28 24>,
				<3 126 126 126 126 126 126 126 126 126 126 126 126 126 126 126 126>,
				<1 0 0 0 0 0 0 0 0 0 0 0 0 0 0 0 0>,
				<1 10 22 22 22 22 22 22 22 22 22 22 22 22 28 28 28>,
				<1 0 0 0 0 0 0 0 0 0 0 0 0 0 0 0 0>,
				<5 126 126 126 126 126 126 126 126 126 126 126 126 126 126 126 126>;
			};
			r23 {
				channels = <128 128>;
				txs-delta = <0 0 0>;
				rates-cck = <126 126 126 126>;
				rates-ofdm = <0 0 0 0 33 33 33 33>;
				rates-mcs =
				<1 26 26 26 26 26 26 26 24 24 30>,
				<1 30 28 28 24 24 30 30 30 30 30>,
				<2 126 126 126 126 126 126 126 126 126 126>;
				rates-ru =
				<1 33 33 32 32 33 33 33 33 33 32 32 32>,
				<1 30 30 30 30 30 30 30 30 28 28 0 0>,
				<1 0 0 0 0 0 10 10 10 10 10 10 10>,
				<1 26 26 26 26 26 26 26 24 24 30 30 30>,
				<1 30 28 28 24 24 30 30 30 30 30 30 30>,
				<2 126 126 126 126 126 126 126 126 126 126 126 126>;
				rates-eht-ru =
				<1 33 33 32 32 33 33 33 33 33 32 32 32 32 0 0 0>,
				<1 30 30 30 30 30 30 30 30 28 28 0 0 0 0 0 0>,
				<1 0 0 0 0 0 10 10 10 10 10 10 10 10 10 10 10>,
				<1 26 26 26 26 26 26 26 24 24 30 30 30 30 30 30 30>,
				<1 30 28 28 24 24 30 30 30 30 30 30 30 30 28 28 24>,
				<3 126 126 126 126 126 126 126 126 126 126 126 126 126 126 126 126>,
				<1 0 0 0 0 0 0 0 0 0 0 0 0 0 0 0 0>,
				<1 10 18 18 18 18 18 18 18 18 18 18 18 18 26 26 26>,
				<1 0 0 0 0 0 0 0 0 0 0 0 0 0 0 0 0>,
				<5 126 126 126 126 126 126 126 126 126 126 126 126 126 126 126 126>;
			};
			r24 {
				channels = <132 132>;
				txs-delta = <0 0 0>;
				rates-cck = <126 126 126 126>;
				rates-ofdm = <0 0 0 0 33 33 33 33>;
				rates-mcs =
				<1 22 22 22 22 22 22 22 22 22 27>,
				<1 27 27 27 24 24 28 28 28 28 28>,
				<2 126 126 126 126 126 126 126 126 126 126>;
				rates-ru =
				<1 33 33 32 32 33 33 33 33 33 32 32 32>,
				<1 28 28 28 28 28 28 28 28 28 28 0 0>,
				<1 0 0 0 0 0 6 6 6 6 6 6 6>,
				<1 22 22 22 22 22 22 22 22 22 27 27 27>,
				<1 27 27 27 24 24 28 28 28 28 28 28 28>,
				<2 126 126 126 126 126 126 126 126 126 126 126 126>;
				rates-eht-ru =
				<1 33 33 32 32 33 33 33 33 33 32 32 32 32 0 0 0>,
				<1 28 28 28 28 28 28 28 28 28 28 0 0 0 30 30 30>,
				<1 0 0 0 0 0 6 6 6 6 6 6 6 6 6 6 6>,
				<1 22 22 22 22 22 22 22 22 22 27 27 27 27 27 27 27>,
				<1 27 27 27 24 24 28 28 28 28 28 28 28 28 28 28 24>,
				<3 126 126 126 126 126 126 126 126 126 126 126 126 126 126 126 126>,
				<1 30 30 30 30 30 28 28 0 0 0 0 0 0 0 0 0>,
				<1 6 16 16 16 16 16 16 16 16 16 16 16 16 22 22 22>,
				<1 30 30 30 30 30 30 30 30 28 28 24 24 0 0 0 0>,
				<5 126 126 126 126 126 126 126 126 126 126 126 126 126 126 126 126>;
			};
			r25 {
				channels = <136 136>;
				txs-delta = <0 0 0>;
				rates-cck = <126 126 126 126>;
				rates-ofdm = <0 0 0 0 31 31 31 31>;
				rates-mcs =
				<1 18 18 18 18 18 18 18 18 18 27>,
				<1 27 27 27 24 24 28 28 28 28 28>,
				<2 126 126 126 126 126 126 126 126 126 126>;
				rates-ru =
				<1 31 31 31 31 29 29 29 29 29 29 29 29>,
				<1 28 28 28 28 28 28 28 28 28 28 0 0>,
				<1 0 0 0 0 0 4 4 4 4 4 4 4>,
				<1 18 18 18 18 18 18 18 18 18 27 27 27>,
				<1 27 27 27 24 24 28 28 28 28 28 28 28>,
				<2 126 126 126 126 126 126 126 126 126 126 126 126>;
				rates-eht-ru =
				<1 31 31 31 31 29 29 29 29 29 29 29 29 29 0 0 0>,
				<1 28 28 28 28 28 28 28 28 28 28 0 0 0 30 30 30>,
				<1 0 0 0 0 0 4 4 4 4 4 4 4 4 4 4 4>,
				<1 18 18 18 18 18 18 18 18 18 27 27 27 27 27 27 27>,
				<1 27 27 27 24 24 28 28 28 28 28 28 28 28 28 28 24>,
				<3 126 126 126 126 126 126 126 126 126 126 126 126 126 126 126 126>,
				<1 30 30 30 30 30 28 28 0 0 0 0 0 0 0 0 0>,
				<1 4 12 12 12 12 12 12 12 12 12 12 12 12 18 18 18>,
				<1 30 30 30 30 30 30 30 30 28 28 24 24 0 0 0 0>,
				<5 126 126 126 126 126 126 126 126 126 126 126 126 126 126 126 126>;
			};
			r26 {
				channels = <140 140>;
				txs-delta = <0 0 0>;
				rates-cck = <126 126 126 126>;
				rates-ofdm = <0 0 0 0 27 27 27 27>;
				rates-mcs =
				<1 18 18 18 18 18 18 18 18 18 25>,
				<1 25 25 25 24 24 30 30 30 30 30>,
				<2 126 126 126 126 126 126 126 126 126 126>;
				rates-ru =
				<1 27 27 27 27 25 25 25 25 25 25 25 25>,
				<1 32 32 32 32 32 30 30 30 28 28 0 0>,
				<1 0 0 0 0 0 4 4 4 4 4 4 4>,
				<1 18 18 18 18 18 18 18 18 18 25 25 25>,
				<1 25 25 25 24 24 30 30 30 30 30 30 30>,
				<2 126 126 126 126 126 126 126 126 126 126 126 126>;
				rates-eht-ru =
				<1 27 27 27 27 25 25 25 25 25 25 25 25 25 0 0 0>,
				<1 32 32 32 32 32 30 30 30 28 28 0 0 0 30 30 30>,
				<1 0 0 0 0 0 4 4 4 4 4 4 4 4 4 4 4>,
				<1 18 18 18 18 18 18 18 18 18 25 25 25 25 25 25 25>,
				<1 25 25 25 24 24 30 30 30 30 30 30 30 30 28 28 24>,
				<3 126 126 126 126 126 126 126 126 126 126 126 126 126 126 126 126>,
				<1 30 30 30 30 30 28 28 0 0 0 0 0 0 0 0 0>,
				<1 4 12 12 12 12 12 12 12 12 12 12 12 12 18 18 18>,
				<1 30 30 30 30 30 30 30 30 28 28 24 24 0 0 0 0>,
				<5 126 126 126 126 126 126 126 126 126 126 126 126 126 126 126 126>;
			};
			r27 {
				channels = <144 144>;
				txs-delta = <0 0 0>;
				rates-cck = <126 126 126 126>;
				rates-ofdm = <0 0 0 0 32 32 32 32>;
				rates-mcs =
				<1 28 28 28 28 28 28 28 24 24 30>,
				<1 30 28 28 24 24 30 30 30 30 30>,
				<2 126 126 126 126 126 126 126 126 126 126>;
				rates-ru =
				<1 32 32 32 32 33 33 33 33 33 32 32 32>,
				<1 32 32 32 32 32 30 30 30 28 28 0 0>,
				<1 0 0 0 0 0 18 18 18 18 18 18 18>,
				<1 28 28 28 28 28 28 28 24 24 30 30 30>,
				<1 30 28 28 24 24 30 30 30 30 30 30 30>,
				<2 126 126 126 126 126 126 126 126 126 126 126 126>;
				rates-eht-ru =
				<1 32 32 32 32 33 33 33 33 33 32 32 32 32 0 0 0>,
				<1 32 32 32 32 32 30 30 30 28 28 0 0 0 30 30 30>,
				<1 0 0 0 0 0 18 18 18 18 18 18 18 18 18 18 18>,
				<1 28 28 28 28 28 28 28 24 24 30 30 30 30 30 30 30>,
				<1 30 28 28 24 24 30 30 30 30 30 30 30 30 28 28 24>,
				<3 126 126 126 126 126 126 126 126 126 126 126 126 126 126 126 126>,
				<1 30 30 30 30 30 28 28 0 0 0 0 0 0 0 0 0>,
				<1 18 24 24 24 24 24 24 24 24 24 24 24 24 28 28 28>,
				<1 30 30 30 30 30 30 30 30 28 28 24 24 0 0 0 0>,
				<5 126 126 126 126 126 126 126 126 126 126 126 126 126 126 126 126>;
			};
			r28 {
				channels = <149 161>;
				txs-delta = <0 0 0>;
				rates-cck = <126 126 126 126>;
				rates-ofdm = <0 0 0 0 33 33 33 33>;
				rates-mcs =
				<1 25 25 25 25 25 25 25 24 24 28>,
				<1 28 28 28 24 24 30 30 30 30 30>,
				<2 126 126 126 126 126 126 126 126 126 126>;
				rates-ru =
				<1 33 33 32 32 33 33 33 33 33 32 32 32>,
				<1 32 32 32 32 32 30 30 30 28 28 0 0>,
				<1 0 0 0 0 0 16 16 16 16 16 16 16>,
				<1 25 25 25 25 25 25 25 24 24 28 28 28>,
				<1 28 28 28 24 24 30 30 30 30 30 30 30>,
				<2 126 126 126 126 126 126 126 126 126 126 126 126>;
				rates-eht-ru =
				<1 33 33 32 32 33 33 33 33 33 32 32 32 32 0 0 0>,
				<1 32 32 32 32 32 30 30 30 28 28 0 0 0 30 30 30>,
				<1 0 0 0 0 0 16 16 16 16 16 16 16 16 16 16 16>,
				<1 25 25 25 25 25 25 25 24 24 28 28 28 28 28 28 28>,
				<1 28 28 28 24 24 30 30 30 30 30 30 30 30 28 28 24>,
				<3 126 126 126 126 126 126 126 126 126 126 126 126 126 126 126 126>,
				<1 30 30 30 30 30 28 28 0 0 0 0 0 0 0 0 0>,
				<1 16 20 20 20 20 20 20 20 20 20 20 20 20 25 25 25>,
				<1 30 30 30 30 30 30 30 30 28 28 24 24 0 0 0 0>,
				<5 126 126 126 126 126 126 126 126 126 126 126 126 126 126 126 126>;
			};
			r29 {
				channels = <165 165>;
				txs-delta = <0 0 0>;
				rates-cck = <126 126 126 126>;
				rates-ofdm = <0 0 0 0 33 33 33 33>;
				rates-mcs =
				<1 33 33 32 32 32 28 28 26 26 33>,
				<1 32 28 28 26 26 0 0 0 0 0>,
				<2 126 126 126 126 126 126 126 126 126 126>;
				rates-ru =
				<1 33 33 32 32 33 33 33 33 33 32 32 32>,
				<1 0 0 0 0 0 0 0 0 0 0 0 0>,
				<1 0 0 0 0 0 33 33 33 33 33 32 32>,
				<1 33 33 32 32 32 28 28 26 26 33 33 33>,
				<1 32 28 28 26 26 0 0 0 0 0 0 0>,
				<2 126 126 126 126 126 126 126 126 126 126 126 126>;
				rates-eht-ru =
				<1 33 33 32 32 33 33 33 33 33 32 32 32 32 0 0 0>,
				<1 0 0 0 0 0 0 0 0 0 0 0 0 0 0 0 0>,
				<1 0 0 0 0 0 33 33 33 33 33 32 32 32 28 28 26>,
				<1 33 33 32 32 32 28 28 26 26 33 33 33 33 33 32 32>,
				<1 32 28 28 26 26 0 0 0 0 0 0 0 0 0 0 0>,
				<3 126 126 126 126 126 126 126 126 126 126 126 126 126 126 126 126>,
				<1 0 0 0 0 0 0 0 0 0 0 0 0 0 0 0 0>,
				<1 26 33 33 33 33 33 32 32 32 28 28 26 26 33 33 33>,
				<1 0 0 0 0 0 0 0 0 0 0 0 0 0 0 0 0>,
				<5 126 126 126 126 126 126 126 126 126 126 126 126 126 126 126 126>;
			};
			r30 {
				channels = <169 169>;
				txs-delta = <0 0 0>;
				rates-cck = <126 126 126 126>;
				rates-ofdm = <0 0 0 0 0 0 0 0>;
				rates-mcs =
				<2 0 0 0 0 0 0 0 0 0 0>,
				<2 126 126 126 126 126 126 126 126 126 126>;
				rates-ru =
				<5 0 0 0 0 0 0 0 0 0 0 0 0>,
				<2 126 126 126 126 126 126 126 126 126 126 126 126>;
				rates-eht-ru =
				<5 0 0 0 0 0 0 0 0 0 0 0 0 0 0 0 0>,
				<3 126 126 126 126 126 126 126 126 126 126 126 126 126 126 126 126>,
				<3 0 0 0 0 0 0 0 0 0 0 0 0 0 0 0 0>,
				<5 126 126 126 126 126 126 126 126 126 126 126 126 126 126 126 126>;
			};
			r31 {
				channels = <173 173>;
				txs-delta = <0 0 0>;
				rates-cck = <126 126 126 126>;
				rates-ofdm = <0 0 0 0 0 0 0 0>;
				rates-mcs =
				<2 0 0 0 0 0 0 0 0 0 0>,
				<2 126 126 126 126 126 126 126 126 126 126>;
				rates-ru =
				<5 0 0 0 0 0 0 0 0 0 0 0 0>,
				<2 126 126 126 126 126 126 126 126 126 126 126 126>;
				rates-eht-ru =
				<5 0 0 0 0 0 0 0 0 0 0 0 0 0 0 0 0>,
				<3 126 126 126 126 126 126 126 126 126 126 126 126 126 126 126 126>,
				<3 0 0 0 0 0 0 0 0 0 0 0 0 0 0 0 0>,
				<5 126 126 126 126 126 126 126 126 126 126 126 126 126 126 126 126>;
			};
			r32 {
				channels = <177 177>;
				txs-delta = <0 0 0>;
				rates-cck = <126 126 126 126>;
				rates-ofdm = <0 0 0 0 0 0 0 0>;
				rates-mcs =
				<2 0 0 0 0 0 0 0 0 0 0>,
				<2 126 126 126 126 126 126 126 126 126 126>;
				rates-ru =
				<5 0 0 0 0 0 0 0 0 0 0 0 0>,
				<2 126 126 126 126 126 126 126 126 126 126 126 126>;
				rates-eht-ru =
				<5 0 0 0 0 0 0 0 0 0 0 0 0 0 0 0 0>,
				<3 126 126 126 126 126 126 126 126 126 126 126 126 126 126 126 126>,
				<3 0 0 0 0 0 0 0 0 0 0 0 0 0 0 0 0>,
				<5 126 126 126 126 126 126 126 126 126 126 126 126 126 126 126 126>;
			};
			r33 {
				channels = <181 181>;
				txs-delta = <0 0 0>;
				rates-cck = <126 126 126 126>;
				rates-ofdm = <0 0 0 0 0 0 0 0>;
				rates-mcs =
				<2 0 0 0 0 0 0 0 0 0 0>,
				<2 126 126 126 126 126 126 126 126 126 126>;
				rates-ru =
				<5 0 0 0 0 0 0 0 0 0 0 0 0>,
				<2 126 126 126 126 126 126 126 126 126 126 126 126>;
				rates-eht-ru =
				<5 0 0 0 0 0 0 0 0 0 0 0 0 0 0 0 0>,
				<3 126 126 126 126 126 126 126 126 126 126 126 126 126 126 126 126>,
				<3 0 0 0 0 0 0 0 0 0 0 0 0 0 0 0 0>,
				<5 126 126 126 126 126 126 126 126 126 126 126 126 126 126 126 126>;
			};
		};
	};
};
